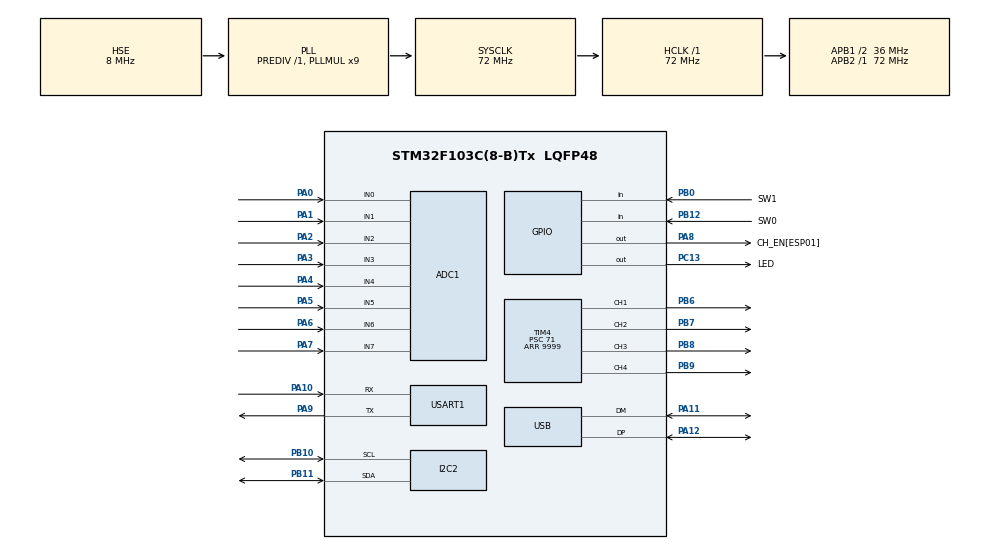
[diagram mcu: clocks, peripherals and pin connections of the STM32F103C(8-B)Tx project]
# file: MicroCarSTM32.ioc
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ADC1.Channel-0\#ChannelRegularConversion=ADC_CHANNEL_0
ADC1.Channel-1\#ChannelRegularConversion=ADC_CHANNEL_1
ADC1.Channel-2\#ChannelRegularConversion=ADC_CHANNEL_2
ADC1.Channel-3\#ChannelRegularConversion=ADC_CHANNEL_3
ADC1.Channel-4\#ChannelRegularConversion=ADC_CHANNEL_4
ADC1.Channel-5\#ChannelRegularConversion=ADC_CHANNEL_5
ADC1.Channel-6\#ChannelRegularConversion=ADC_CHANNEL_6
ADC1.Channel-7\#ChannelRegularConversion=ADC_CHANNEL_7
ADC1.NbrOfConversion=8
ADC1.NbrOfConversionFlag=1
ADC1.Rank-0\#ChannelRegularConversion=1
ADC1.Rank-1\#ChannelRegularConversion=2
ADC1.Rank-2\#ChannelRegularConversion=3
ADC1.Rank-3\#ChannelRegularConversion=4
ADC1.Rank-4\#ChannelRegularConversion=5
ADC1.Rank-5\#ChannelRegularConversion=6
ADC1.Rank-6\#ChannelRegularConversion=7
ADC1.Rank-7\#ChannelRegularConversion=8
ADC1.SamplingTime-0\#ChannelRegularConversion=ADC_SAMPLETIME_55CYCLES_5
ADC1.SamplingTime-1\#ChannelRegularConversion=ADC_SAMPLETIME_55CYCLES_5
ADC1.SamplingTime-2\#ChannelRegularConversion=ADC_SAMPLETIME_55CYCLES_5
ADC1.SamplingTime-3\#ChannelRegularConversion=ADC_SAMPLETIME_55CYCLES_5
ADC1.SamplingTime-4\#ChannelRegularConversion=ADC_SAMPLETIME_55CYCLES_5
ADC1.SamplingTime-5\#ChannelRegularConversion=ADC_SAMPLETIME_55CYCLES_5
ADC1.SamplingTime-6\#ChannelRegularConversion=ADC_SAMPLETIME_55CYCLES_5
ADC1.SamplingTime-7\#ChannelRegularConversion=ADC_SAMPLETIME_55CYCLES_5
ADC1.master=1
Dma.ADC1.0.Direction=DMA_PERIPH_TO_MEMORY
Dma.ADC1.0.Instance=DMA1_Channel1
Dma.ADC1.0.MemDataAlignment=DMA_MDATAALIGN_HALFWORD
Dma.ADC1.0.MemInc=DMA_MINC_ENABLE
Dma.ADC1.0.Mode=DMA_NORMAL
Dma.ADC1.0.PeriphDataAlignment=DMA_PDATAALIGN_HALFWORD
Dma.ADC1.0.PeriphInc=DMA_PINC_DISABLE
Dma.ADC1.0.Priority=DMA_PRIORITY_LOW
Dma.I2C2_RX.1.Direction=DMA_PERIPH_TO_MEMORY
Dma.I2C2_RX.1.Instance=DMA1_Channel5
Dma.I2C2_RX.1.MemDataAlignment=DMA_MDATAALIGN_BYTE
Dma.I2C2_RX.1.MemInc=DMA_MINC_ENABLE
Dma.I2C2_RX.1.Mode=DMA_NORMAL
Dma.I2C2_RX.1.PeriphDataAlignment=DMA_PDATAALIGN_WORD
Dma.I2C2_RX.1.PeriphInc=DMA_PINC_DISABLE
Dma.I2C2_RX.1.Priority=DMA_PRIORITY_LOW
Dma.I2C2_TX.2.Direction=DMA_MEMORY_TO_PERIPH
Dma.I2C2_TX.2.Instance=DMA1_Channel4
Dma.I2C2_TX.2.MemDataAlignment=DMA_MDATAALIGN_BYTE
Dma.I2C2_TX.2.MemInc=DMA_MINC_ENABLE
Dma.I2C2_TX.2.Mode=DMA_NORMAL
Dma.I2C2_TX.2.PeriphDataAlignment=DMA_PDATAALIGN_BYTE
Dma.I2C2_TX.2.PeriphInc=DMA_PINC_DISABLE
Dma.I2C2_TX.2.Priority=DMA_PRIORITY_LOW
Dma.Request0=ADC1
Dma.Request1=I2C2_RX
Dma.Request2=I2C2_TX
I2C2.I2C_Mode=I2C_Fast
Mcu.Family=STM32F1
Mcu.Name=STM32F103C(8-B)Tx
Mcu.Package=LQFP48
NVIC.DMA1_Channel1_IRQn=true\:0\:0\:false\:false\:true\:false\:true\:true
NVIC.DMA1_Channel4_IRQn=true\:0\:0\:false\:false\:true\:false\:true\:true
NVIC.DMA1_Channel5_IRQn=true\:0\:0\:false\:false\:true\:false\:true\:true
NVIC.I2C2_EV_IRQn=true\:0\:0\:false\:false\:true\:true\:true\:true
NVIC.PriorityGroup=NVIC_PRIORITYGROUP_4
NVIC.TIM1_UP_IRQn=true\:0\:0\:false\:false\:true\:true\:true\:true
NVIC.USART1_IRQn=true\:0\:0\:false\:false\:true\:true\:true\:true
NVIC.USB_LP_CAN1_RX0_IRQn=true\:0\:0\:false\:false\:true\:false\:true\:true
PA0-WKUP.Signal=ADCx_IN0
PA1.Signal=ADCx_IN1
PA10.Mode=Asynchronous
PA10.Signal=USART1_RX
PA11.Mode=Device
PA11.Signal=USB_DM
PA12.Mode=Device
PA12.Signal=USB_DP
PA13.Mode=Serial_Wire
PA13.Signal=SYS_JTMS-SWDIO
PA14.Mode=Serial_Wire
PA14.Signal=SYS_JTCK-SWCLK
PA2.Signal=ADCx_IN2
PA3.Signal=ADCx_IN3
PA4.Signal=ADCx_IN4
PA5.Signal=ADCx_IN5
PA6.Signal=ADCx_IN6
PA7.Signal=ADCx_IN7
PA8.GPIO_Label=CH_EN[ESP01]
PA8.Signal=GPIO_Output
PA9.Mode=Asynchronous
PA9.Signal=USART1_TX
PB0.GPIO_Label=SW1
PB0.GPIO_PuPd=GPIO_PULLUP
PB0.Signal=GPIO_Input
PB10.Mode=I2C
PB10.Signal=I2C2_SCL
PB11.Mode=I2C
PB11.Signal=I2C2_SDA
PB12.GPIO_Label=SW0
PB12.Signal=GPIO_Input
PB6.Signal=S_TIM4_CH1
PB7.Signal=S_TIM4_CH2
PB8.Signal=S_TIM4_CH3
PB9.Signal=S_TIM4_CH4
PC13-TAMPER-RTC.GPIO_Label=LED
PC13-TAMPER-RTC.Signal=GPIO_Output
PC14-OSC32_IN.Mode=LSE-External-Oscillator
PC14-OSC32_IN.Signal=RCC_OSC32_IN
PC15-OSC32_OUT.Mode=LSE-External-Oscillator
PC15-OSC32_OUT.Signal=RCC_OSC32_OUT
PD0-OSC_IN.Mode=HSE-External-Oscillator
PD0-OSC_IN.Signal=RCC_OSC_IN
PD1-OSC_OUT.Mode=HSE-External-Oscillator
PD1-OSC_OUT.Signal=RCC_OSC_OUT
ProjectManager.HeapSize=0x200
ProjectManager.StackSize=0x400
ProjectManager.TargetToolchain=STM32CubeIDE
RCC.ADCPresc=RCC_ADCPCLK2_DIV6
RCC.AHBFreq_Value=72000000
RCC.APB1CLKDivider=RCC_HCLK_DIV2
RCC.APB1Freq_Value=36000000
RCC.APB1TimFreq_Value=72000000
RCC.APB2Freq_Value=72000000
RCC.APB2TimFreq_Value=72000000
RCC.HCLKFreq_Value=72000000
RCC.PLLMUL=RCC_PLL_MUL9
RCC.SYSCLKFreq_VALUE=72000000
RCC.SYSCLKSource=RCC_SYSCLKSOURCE_PLLCLK
RCC.USBFreq_Value=48000000
RCC.USBPrescaler=RCC_USBCLKSOURCE_PLL_DIV1_5
SH.ADCx_IN0.0=ADC1_IN0,IN0
SH.ADCx_IN1.0=ADC1_IN1,IN1
SH.ADCx_IN2.0=ADC1_IN2,IN2
SH.ADCx_IN3.0=ADC1_IN3,IN3
SH.ADCx_IN4.0=ADC1_IN4,IN4
SH.ADCx_IN5.0=ADC1_IN5,IN5
SH.ADCx_IN6.0=ADC1_IN6,IN6
SH.ADCx_IN7.0=ADC1_IN7,IN7
SH.S_TIM4_CH1.0=TIM4_CH1,PWM Generation1 CH1
SH.S_TIM4_CH2.0=TIM4_CH2,PWM Generation2 CH2
SH.S_TIM4_CH3.0=TIM4_CH3,PWM Generation3 CH3
SH.S_TIM4_CH4.0=TIM4_CH4,PWM Generation4 CH4
TIM1.Period=249
TIM1.Prescaler=71
TIM4.Channel-PWM\ Generation1\ CH1=TIM_CHANNEL_1
TIM4.Channel-PWM\ Generation2\ CH2=TIM_CHANNEL_2
TIM4.Channel-PWM\ Generation3\ CH3=TIM_CHANNEL_3
TIM4.Channel-PWM\ Generation4\ CH4=TIM_CHANNEL_4
TIM4.Period=9999
TIM4.Prescaler=71
USART1.VirtualMode=VM_ASYNC
USB_DEVICE.APP_RX_DATA_SIZE=256
USB_DEVICE.APP_TX_DATA_SIZE=256
USB_DEVICE.CLASS_NAME_FS=CDC
USB_DEVICE.PID_CDC_FS=0x5740
USB_DEVICE.VID=0x483
USB_DEVICE.VirtualMode=Cdc
USB_DEVICE.VirtualModeFS=Cdc_FS
VP_TIM1_VS_ClockSourceINT.Mode=Internal
VP_TIM4_VS_ClockSourceINT.Mode=Internal
VP_USB_DEVICE_VS_USB_DEVICE_CDC_FS.Mode=CDC_FS
board=custom

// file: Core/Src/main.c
/* USER CODE BEGIN Header */
/**
  ******************************************************************************
  * @file           : main.c
  * @author			: Gerónimo Spiazzi
  * @brief          : Main program body
  ******************************************************************************
  * @attention
  *
  * Copyright (c) 2024 STMicroelectronics.
  * All rights reserved.
  *
  * This software is licensed under terms that can be found in the LICENSE file
  * in the root directory of this software component.
  * If no LICENSE file comes with this software, it is provided AS-IS.
  *
  ******************************************************************************
  */
/* USER CODE END Header */
#include "main.h"
#include "usb_device.h"

/* USER CODE BEGIN Includes */
#include <string.h>
#include "usbd_cdc_if.h"
#include "stm32f1xx_hal_flash.h"
#include "stm32f1xx_hal_flash_ex.h"
#include "ESP01.h"
#include "UNERBUS.h"
#include "BUTTON.h"
#include "INFRARED.h"
#include "MPU6050.h"
#include "OLED.h"
#include "PID.h"
#include "ENGINE.h"
/* USER CODE END Includes */

/* USER CODE BEGIN PTD */
typedef union {
	struct {
		uint8_t	b0:	1;
		uint8_t	b1:	1;
		uint8_t	b2:	1;
		uint8_t	b3:	1;
		uint8_t	b4:	1;
		uint8_t	b5:	1;
		uint8_t	b6:	1;
		uint8_t	b7:	1;
	} bit;
	uint8_t byte;
} _uFlag;

typedef union {
	uint8_t		u8[4];
	int8_t		i8[4];
	uint16_t	u16[2];
	int16_t		i16[2];
	uint32_t	u32;
	int32_t		i32;
} _uWork;

typedef enum {
	// Communication commands
	ACKNOWLEDGE = 0x0D,
	GET_LOCAL_IP = 0xF2,
    ALIVE = 0xF0,
    GET_FIRMWARE_INFO = 0xF1,
	UNKNOWNCMD = 0xFF,

	// 0xA_ : Sensors & Actuators (Read data)
    GET_IR_SENSORS = 0xA0,
	GET_MPU_DATA = 0xA2, //ACCELERATION
	GET_BUTTON_STATE = 0xA4, //BUTTONS
	GET_MOTOR_SPEED = 0xA6,

	// 0xB_ : Sensors (Configuration and calibration)
	SET_IR_CALIBRATION = 0xB0, //CALIBRATION

	// 0xC_ : Actuators and software configuration
	SET_MOTOR_TEST = 0xC0, //TEST_ENGINE
	SET_PWM_CONFIG = 0xC2,
	SET_BATTERY_VOLTAGE = 0xC4,

	// 0xD_ : PID Configuration
	// Turn PID
	SET_PID_TURN_GAINS = 0xD0, //SET_PID
	GET_PID_TURN_GAINS = 0xD1,

	// Wall PID
	SET_PID_WALL_GAINS = 0xD2,
	GET_PID_WALL_GAINS = 0xD3,

	// Stop PID
	SET_PID_STOP_GAINS = 0xD6,
	GET_PID_STOP_GAINS = 0xD7,

	// Movement parameters
	SET_TURN_SPEED = 0xD8,
	SET_WALL_SPEED = 0xDA,

	// Maze status
	SET_ROBOT_MODE = 0xE0,

	GET_CURRENT_ACTION		= 0xEA,

	SET_MAZE_TARGET			= 0xEC,
	SET_MAZE_START			= 0xED,

	GET_INTERSECTION_TYPE	= 0xEE,
	GET_MAP_INFO			= 0xEF,
	GET_SPECIAL_CELL		= 0xE5,

	// Stream Telemetry Mode
	STREAM_TELEMETRY		= 0xE3,
} Command_e;

typedef enum {
	DISPLAY_MENU,
	DISPLAY_IR_SENSORS,
	DISPLAY_MPU,
	DISPLAY_WIFI,
	DISPLAY_MOTORS,
	DISPLAY_SOFTWARE,
	DISPLAY_RUN,
	DISPLAY_RUN_MODE_SELECT,
	DISPLAY_CLEAR,
	DISPLAY_CONFIG_START,
	DISPLAY_CONFIG_TARGET,
	DISPLAY_END_SCREEN,
} DisplayPage_e;

typedef enum {
	MENU_START = 0,
	MENU_IR_DATA,
	MENU_MPU_DATA,
	MENU_WIFI,
	MENU_DRIVE_MOTOR,
	MENU_SOFTWARE_INFO,
	MENU_MAX_OPTIONS,
} MenuOptions_e;

typedef enum {
	MODE_IDLE,
	MODE_FINDING_MARKS,
	MODE_EXPLORING_MAZE,
//	MODE_MAZE_RUNNER,
} Robot_Mode_e;

typedef enum {
	ACTION_IDLE,
	ACTION_FOLLOW_WALL,
	ACTION_CENTER_IN_CELL,
	ACTION_AFTER_TURN,
	ACTION_TURN_PIVOT,
	ACTION_BACK_WALL_ALIGN,
	ACTION_MOTOR_TEST,
} Robot_Action_e;

typedef enum {
	NORTH = 0,
	EAST = 1,
	SOUTH = 2,
	WEST = 3,
} Map_Direction_e;

typedef enum {
	// [Left | Front | Right] -> (L << 2) | (F << 1) | R
	INTERSECTION_CROSSROAD			= 0x00,	// 0b000
	INTERSECTION_LEFT_FRONT_OPEN	= 0x01,	// 0b001
	INTERSECTION_T_ROAD				= 0x02, // 0b010
	INTERSECTION_LEFT_SQUARE		= 0x03,	// 0b011
	INTERSECTION_RIGHT_FRONT_OPEN	= 0x04, // 0b100
	INTERSECTION_UNKNOWN			= 0x05,	// 0b101 Hall
	INTERSECTION_RIGHT_SQUARE		= 0x06,	// 0b110
	INTERSECTION_DEAD_END			= 0x07,	// 0b111
} IntersectionType_e;

typedef enum {
	CELL_INSIDE_CELL,		// Robot navigating inside the cell, normal state
	CELL_FRONT_LINE,		// Front-under sensor detected the line
	CELL_REAR_LINE,			// Rear-under sensor detected the line
	CELL_CROSS_FINISHED,	// Rear-under sensor lost the line (robot is inside a new cell)
//	CELL_ON_MARK,			//
//	CELL_EXITING_MARK,		//
} CellCrossingState_e;

typedef struct {
	uint8_t t1ms;
	uint8_t t10ms;
	uint8_t t20ms;
	uint8_t t100ms;
	uint8_t t500ms;
	uint8_t t1s;
	uint8_t tOutAliveUDP;
} Time_s;

typedef struct {
	uint8_t walls;
	uint8_t visited;
	uint8_t cost;
} CellData_s;

typedef struct {
	CellData_s maze[8][8];
	uint8_t currentX;
	uint8_t currentY;
	uint8_t targetX;
	uint8_t targetY;
} Map_Position_s;

typedef struct {
    uint8_t x;
    uint8_t y;
} Point_s;

typedef struct {
	uint32_t time_frontLineDetect;
	uint32_t time_frontLineLost;
	uint32_t time_rearLineDetect;
	uint32_t time_rearLineLost;
	uint32_t currentVelocity_mm_s;
	uint32_t time_dt_ms;
} VELOCITY_Handle_s;

/*
 * HAL_FLASH_Unlock();
 * CONFIGURAR ESTRUCTURA ERASE
 * EJECUTAR HAL_FLASHEx_Erase
 * Pasar toda la información a la Flash con HAL_FLASH_Program
 * HAL_FLASH_Lock();
 */

/* USER CODE END PTD */

/* USER CODE BEGIN PD */
// Communication buffers size macros
#define SIZEBUFRXPC				128
#define SIZEBUFTXPC				256
#define SIZEBUFRXESP01			128
#define SIZEBUFTXESP01			128

// Heart beat macros
#define	HEARTBEAT_IDLE			0xF4000000
#define	HEARTBEAT_WIFI_READY	0xF5000000
#define	HEARTBEAT_UDP_READY		0xF5400000

// Wi-Fi configuration macros
#define WIFI_SSID				"FCAL"//"FCAL" "InternetPlus_86aa10" "LabPrototip" "InternetPlus_8e2fbb"
#define WIFI_PASSWORD			"fcalconcordia.06-2019"//"fcalconcordia.06-2019" "wlan7955ef" "labproto" "Akhantos2340"
#define WIFI_UDP_REMOTE_IP		"111.22.333.44"//"172.23.229.43"//"192.168.1.18"	//La IP de la PC 172.23.229.43 "192.168.1.31"
#define WIFI_UDP_REMOTE_PORT	30010				//El puerto UDP en la PC
#define WIFI_UDP_LOCAL_PORT		30000

// Display design macros
#define MENU_ITEM_HEIGHT		12 // 10px fuente + 2px espacio
#define MENU_START_Y			14 // Debajo de la línea del header
#define MAX_VISIBLE_ITEMS		4 // Cuántas opciones caben en pantalla a la vez

// Flags macros
#define on1MS					flag1.bit.b0
#define MPU_READ_REQUEST		flag1.bit.b1
#define OLED_UPDATE_REQUEST		flag1.bit.b2
#define I2C_BUS_IS_BUSY			flag1.bit.b3
#define LINE_DETECTED_TURNING	flag1.bit.b4
#define SHOW_EYES_SCREEN		flag1.bit.b5

// Timer counter macros
#define t1MS					timeCounter.t1ms
#define t10MS					timeCounter.t10ms
#define t20MS					timeCounter.t20ms
#define t100MS					timeCounter.t100ms
#define t500MS					timeCounter.t500ms
#define t1S						timeCounter.t1s
#define tOutAliveUDP 			timeCounter.tOutAliveUDP

// Voltage of the batteries (used for PID control of the engines)
#define PID_VOLTAGE					800
#define CURRENT_VOLTAGE				811

// Turn control macros
#define SMOOTH_TURN_OUTER_SPEED		-65
#define SMOOTH_TURN_INNER_SPEED		-35
#define TURN_THRESHOLD				7*YAW_SCALE

#define SMOOTH_TURN_BASE_SPEED		-50
#define SMOOTH_EXIT_OFFSET 			(7 * YAW_SCALE)
#define TURN_MIN_PWM				30

// Wall follow control macros
// Millimeter IR Thresholds
#define WALL_FRONT_THRESHOLD_MM		10
#define WALL_TARGET_DISTANCE_MM		50

// RAW IR THRESHOLDS
#define WALL_FRONT_THRESHOLD		2700 	// Para no chocar la pared de enfrente 			// Casa: 1050 	// Facu: 1200
#define OPEN_CORNER_THRESHOLD		190 	// Para detectar la apertura de una esquina 	// Casa: 320 	// Facu: 170
#define ONE_WALL_TARGET_DISTANCE 	1100 	// Para seguir la pared 						// Casa: 1400 	// Facu: 1100
#define OBJECT_DETECTION_THRESHOLD	180 	// Para detectar pared al otro lado del cruce 	// Casa: 150 	// Facu: 190
#define LINE_DETECTION_THRESHOLD	1600 	// Para detectar la línea de la celda 			// Casa: 1400 	// Facu: 1500
#define LATERAL_WALL_THRESHOLD		800 	// Detectar si hay pared al lado				// Casa: 500 	// Facu: 450

#define WALL_ERROR_DEADZONE			2
#define GYRO_COMPENSATION_GAIN		4 		// Ponderación del giroscopio para mantenerse recto en un cruce con una sola pared

#define DIST_RIGHT_IR				myInfraredValues.millimeterSamples[0]
#define DIST_DIAG_RIGHT_IR			myInfraredValues.millimeterSamples[1]
#define DIST_FRONT_RIGHT_IR			myInfraredValues.millimeterSamples[2]
#define DIST_FRONT_UNDER_IR			myInfraredValues.millimeterSamples[3]
#define DIST_FRONT_LEFT_IR			myInfraredValues.millimeterSamples[4]
#define DIST_DIAG_LEFT_IR			myInfraredValues.millimeterSamples[5]
#define DIST_LEFT_IR				myInfraredValues.millimeterSamples[6]
#define DIST_REAR_UNDER_IR			myInfraredValues.millimeterSamples[7]

#define FILTERED_RIGHT_IR			myInfraredValues.filteredSamples[0]
#define FILTERED_DIAG_RIGHT_IR		myInfraredValues.filteredSamples[1]
#define FILTERED_FRONT_RIGHT_IR		myInfraredValues.filteredSamples[2]
#define FILTERED_FRONT_UNDER_IR		myInfraredValues.filteredSamples[3]
#define FILTERED_FRONT_LEFT_IR		myInfraredValues.filteredSamples[4]
#define FILTERED_DIAG_LEFT_IR		myInfraredValues.filteredSamples[5]
#define FILTERED_LEFT_IR			myInfraredValues.filteredSamples[6]
#define FILTERED_REAR_UNDER_IR		myInfraredValues.filteredSamples[7]

#define DISTANCE_FRONT_TO_REAR_IR	 85 // Millimeter
#define IR_CENTER_DISTANCE_THRESHOLD 1400

#define PERCEPTION_RIGHT			flagsIR.bit.b0
#define PERCEPTION_DIAG_RIGHT		flagsIR.bit.b1
#define	PERCEPTION_FRONT_RIGHT		flagsIR.bit.b2
#define PERCEPTION_FRONT_LEFT		flagsIR.bit.b4
#define PERCEPTION_DIAG_LEFT		flagsIR.bit.b5
#define PERCEPTION_LEFT				flagsIR.bit.b6

#define WALL_NORTH 0x01
#define WALL_EAST 0x02
#define WALL_SOUTH 0x04
#define WALL_WEST 0x08
/* USER CODE END PD */

ADC_HandleTypeDef hadc1;
DMA_HandleTypeDef hdma_adc1;

I2C_HandleTypeDef hi2c2;
DMA_HandleTypeDef hdma_i2c2_rx;
DMA_HandleTypeDef hdma_i2c2_tx;

TIM_HandleTypeDef htim1;
TIM_HandleTypeDef htim4;

UART_HandleTypeDef huart1;

/* USER CODE BEGIN PV */
////////////////////////////// TYPEDEF HANDLERS ///////////////////////////////
volatile _uFlag flag1;
_uWork w;
DisplayPage_e currentPage;
MenuOptions_e currentMenu;
Command_e cmds;
Time_s timeCounter;

static _uFlag flagsIR;
static InfraredHandle_s myInfraredValues;
static MPU_Handle_s myMpuValues;
static OLED_Handle_s myOled;
static PIDHandle_s myTurnValues, myWallValues, mySmoothTurnValues, myStopValues, myReverseValues;
static ENGINE_Handle_s myEngines;
static BUTTON_Handle_s myButton1;
static VELOCITY_Handle_s myVelocity;
/////////////////////////// COMMUNICATION VARIABLES ////////////////////////////
_sESP01Handle esp01;
_sUNERBUSHandle unerbusPC;
_sUNERBUSHandle unerbusESP01;

char localIP[16];

uint8_t bufRXPC[SIZEBUFRXPC], bufTXPC[SIZEBUFTXPC];
uint8_t bufRXESP01[SIZEBUFRXESP01], bufTXESP01[SIZEBUFTXESP01], dataRXESP01;

uint8_t rxUSBData, newData;

static uint8_t i2c_start_timeout = 0;
////////////////////////////// HEARTBEAT VARIABLES /////////////////////////////
uint16_t mask, moveMask;

//////////////////////////// DISPLAY & MENU VARIABLES //////////////////////////
const char* menuItems[] = {
	"Run", 		// "Run           ",
    "Infrared", // "Infrared      ",
    "Motion",
    "Wi-Fi",
    "Motors", 	// "Motors        ",
    "Software"
};

const int8_t totalMenuItems = 6;
int8_t currentSelection;
int8_t scrollOffset;
uint8_t runConfigStep = 0;
//////////////////////////////// OTHER VARIABLES ///////////////////////////////
// Robot control and algorithm variables
Robot_Mode_e currentMode;
Robot_Mode_e selectedRunMode;
Robot_Action_e currentAction;

CellCrossingState_e cellState;

Map_Position_s currentPosition;
Map_Direction_e currentDirection = NORTH;

IntersectionType_e detectedIntersection;

uint8_t intersectionType;
int16_t pivotDegreesTarget;

uint8_t markDetected = 0, marksCount = 0, currentMarkTargetIndex = 0;;
Point_s markLocations[3];

uint8_t showIrInMillimeters;

uint8_t activeLeftWall = 0;
uint8_t activeRightWall = 0;

int32_t wallFollowTargetYaw = 0;
uint16_t referenceLeftWall = 0, referenceRightWall = 0;

uint8_t exitTurn;
uint32_t timeToCenter, centeringStartTime, alignStartTime;

uint8_t marksFound;

char strAux[20];

// EEPROM SIMULATION
const uint8_t varEeprom[] __attribute__ ((__section__ (".configeeprom"))) =
		{0xff, 0xff, 0xff, 0xff, 0xff, 0xff, 0xff, 0xff, 0xff, 0xff, 0xff, 0xff, 0xff, 0xff, 0xff, 0xff,
		0xff, 0xff, 0xff, 0xff, 0xff, 0xff, 0xff, 0xff, 0xff, 0xff, 0xff, 0xff, 0xff, 0xff, 0xff, 0xff,
		0xff, 0xff, 0xff, 0xff, 0xff, 0xff, 0xff, 0xff, 0xff, 0xff, 0xff, 0xff, 0xff, 0xff, 0xff, 0xff,
		0xff, 0xff, 0xff, 0xff, 0xff, 0xff, 0xff, 0xff, 0xff, 0xff, 0xff, 0xff, 0xff, 0xff, 0xff, 0xff,
		0xff, 0xff, 0xff, 0xff, 0xff, 0xff, 0xff, 0xff, 0xff, 0xff, 0xff, 0xff, 0xff, 0xff, 0xff, 0xff,
		0xff, 0xff, 0xff, 0xff, 0xff, 0xff, 0xff, 0xff, 0xff, 0xff, 0xff, 0xff, 0xff, 0xff, 0xff, 0xff,
		0xff, 0xff, 0xff, 0xff, 0xff, 0xff, 0xff, 0xff, 0xff, 0xff, 0xff, 0xff, 0xff, 0xff, 0xff, 0xff,
		0xff, 0xff, 0xff, 0xff, 0xff, 0xff, 0xff, 0xff, 0xff, 0xff, 0xff, 0xff, 0xff, 0xff, 0xff, 0xff,
		0xff, 0xff, 0xff, 0xff, 0xff, 0xff, 0xff, 0xff, 0xff, 0xff, 0xff, 0xff, 0xff, 0xff, 0xff, 0xff,
		0xff, 0xff, 0xff, 0xff, 0xff, 0xff, 0xff, 0xff, 0xff, 0xff, 0xff, 0xff, 0xff, 0xff, 0xff, 0xff,
		0xff, 0xff, 0xff, 0xff, 0xff, 0xff, 0xff, 0xff, 0xff, 0xff, 0xff, 0xff, 0xff, 0xff, 0xff, 0xff,
		0xff, 0xff, 0xff, 0xff, 0xff, 0xff, 0xff, 0xff, 0xff, 0xff, 0xff, 0xff, 0xff, 0xff, 0xff, 0xff,
		0xff, 0xff, 0xff, 0xff, 0xff, 0xff, 0xff, 0xff, 0xff, 0xff, 0xff, 0xff, 0xff, 0xff, 0xff, 0xff,
		0xff, 0xff, 0xff, 0xff, 0xff, 0xff, 0xff, 0xff, 0xff, 0xff, 0xff, 0xff, 0xff, 0xff, 0xff, 0xff,
		0xff, 0xff, 0xff, 0xff, 0xff, 0xff, 0xff, 0xff, 0xff, 0xff, 0xff, 0xff, 0xff, 0xff, 0xff, 0xff,
		0xff, 0xff, 0xff, 0xfe, 0x00, 0x00, 0x00, 0x07, 0xff, 0xf0, 0x00, 0x00, 0x00, 0x00, 0xff, 0xff,
		0xff, 0xff, 0xff, 0xf0, 0x00, 0x00, 0x00, 0x07, 0xff, 0x80, 0x00, 0x00, 0x00, 0x00, 0xff, 0xff,
		0xff, 0xff, 0xff, 0x80, 0x00, 0x00, 0x00, 0x0f, 0xfe, 0x00, 0x00, 0x00, 0x00, 0x01, 0xff, 0xff,
		0xff, 0xff, 0xfe, 0x00, 0x00, 0x00, 0x00, 0x1f, 0xf8, 0x00, 0x00, 0x00, 0x00, 0x03, 0xff, 0xff,
		0xff, 0xff, 0xfc, 0x00, 0x00, 0x00, 0x00, 0x3f, 0xf0, 0x00, 0x00, 0x00, 0x00, 0x07, 0xff, 0xff,
		0xff, 0xff, 0xf8, 0x00, 0x00, 0x00, 0x00, 0x3f, 0xf0, 0x00, 0x00, 0x00, 0x00, 0x07, 0xff, 0xff,
		0xff, 0xff, 0xf0, 0x00, 0x00, 0x00, 0x00, 0x7f, 0xe0, 0x00, 0x00, 0x00, 0x00, 0x0f, 0xff, 0xff,
		0xff, 0xff, 0xe0, 0x00, 0x00, 0x00, 0x00, 0xff, 0xe0, 0x00, 0x00, 0x00, 0x00, 0x1f, 0xff, 0xff,
		0xff, 0xff, 0xc0, 0x00, 0x00, 0x00, 0x01, 0xff, 0xc0, 0x00, 0x00, 0x00, 0x00, 0x3f, 0xff, 0xff,
		0xff, 0xff, 0x80, 0x00, 0x7f, 0xff, 0xff, 0xff, 0xc0, 0x03, 0xff, 0xff, 0xff, 0xff, 0xff, 0xff,
		0xff, 0xff, 0x80, 0x03, 0xff, 0xff, 0xff, 0xff, 0xc0, 0x07, 0xff, 0xff, 0xff, 0xff, 0xff, 0xff,
		0xff, 0xff, 0x00, 0x07, 0xff, 0xff, 0xff, 0xff, 0xc0, 0x0f, 0xff, 0xff, 0xff, 0xff, 0xff, 0xff,
		0xff, 0xff, 0x00, 0x0f, 0xff, 0xff, 0xff, 0xff, 0xc0, 0x07, 0xff, 0xff, 0xff, 0xff, 0xff, 0xff,
		0xff, 0xff, 0x00, 0x1f, 0xfc, 0x00, 0x00, 0x07, 0xc0, 0x07, 0xff, 0xff, 0xff, 0xff, 0xff, 0xff,
		0xff, 0xff, 0x00, 0x1f, 0xf8, 0x00, 0x00, 0x07, 0xe0, 0x00, 0x00, 0x00, 0x00, 0x7f, 0xff, 0xff,
		0xff, 0xfe, 0x00, 0x3f, 0xf0, 0x00, 0x00, 0x07, 0xe0, 0x00, 0x00, 0x00, 0x00, 0x0f, 0xff, 0xff,
		0xff, 0xfe, 0x00, 0x3f, 0xe0, 0x00, 0x00, 0x07, 0xf0, 0x00, 0x00, 0x00, 0x00, 0x01, 0xff, 0xff,
		0xff, 0xfe, 0x00, 0x3f, 0xc0, 0x00, 0x00, 0x07, 0xf8, 0x00, 0x00, 0x00, 0x00, 0x00, 0xff, 0xff,
		0xff, 0xfe, 0x00, 0x3f, 0x80, 0x00, 0x00, 0x07, 0xfc, 0x00, 0x00, 0x00, 0x00, 0x00, 0xff, 0xff,
		0xff, 0xff, 0x00, 0x3f, 0x00, 0x00, 0x00, 0x07, 0xff, 0x00, 0x00, 0x00, 0x00, 0x00, 0x7f, 0xff,
		0xff, 0xff, 0x00, 0x3f, 0x00, 0x00, 0x00, 0x07, 0xff, 0xe0, 0x00, 0x00, 0x00, 0x00, 0x7f, 0xff,
		0xff, 0xff, 0x00, 0x1f, 0xff, 0xff, 0xc0, 0x07, 0xff, 0xff, 0xff, 0xff, 0xfe, 0x00, 0x3f, 0xff,
		0xff, 0xff, 0x00, 0x0f, 0xff, 0xff, 0xc0, 0x07, 0xff, 0xff, 0xff, 0xff, 0xfe, 0x00, 0x3f, 0xff,
		0xff, 0xff, 0x80, 0x07, 0xff, 0xff, 0xc0, 0x07, 0xff, 0xff, 0xff, 0xff, 0xff, 0x00, 0x3f, 0xff,
		0xff, 0xff, 0x80, 0x03, 0xff, 0xff, 0xc0, 0x07, 0xff, 0xff, 0xff, 0xff, 0xfe, 0x00, 0x3f, 0xff,
		0xff, 0xff, 0xc0, 0x00, 0xff, 0xff, 0xc0, 0x07, 0xff, 0xff, 0xff, 0xff, 0xfe, 0x00, 0x3f, 0xff,
		0xff, 0xff, 0xc0, 0x00, 0x00, 0x00, 0x00, 0x07, 0xff, 0x00, 0x00, 0x00, 0x00, 0x00, 0x7f, 0xff,
		0xff, 0xff, 0xe0, 0x00, 0x00, 0x00, 0x00, 0x07, 0xfe, 0x00, 0x00, 0x00, 0x00, 0x00, 0x7f, 0xff,
		0xff, 0xff, 0xf0, 0x00, 0x00, 0x00, 0x00, 0x07, 0xfc, 0x00, 0x00, 0x00, 0x00, 0x00, 0x7f, 0xff,
		0xff, 0xff, 0xf8, 0x00, 0x00, 0x00, 0x00, 0x07, 0xf8, 0x00, 0x00, 0x00, 0x00, 0x00, 0xff, 0xff,
		0xff, 0xff, 0xfc, 0x00, 0x00, 0x00, 0x00, 0x07, 0xf0, 0x00, 0x00, 0x00, 0x00, 0x00, 0xff, 0xff,
		0xff, 0xff, 0xff, 0x00, 0x00, 0x00, 0x00, 0x07, 0xf0, 0x00, 0x00, 0x00, 0x00, 0x01, 0xff, 0xff,
		0xff, 0xff, 0xff, 0xc0, 0x00, 0x00, 0x00, 0x07, 0xe0, 0x00, 0x00, 0x00, 0x00, 0x07, 0xff, 0xff,
		0xff, 0xff, 0xff, 0xf8, 0x00, 0x00, 0x00, 0x07, 0xc0, 0x00, 0x00, 0x00, 0x00, 0x1f, 0xff, 0xff,
		0xff, 0xff, 0xff, 0xff, 0x80, 0x00, 0x00, 0x07, 0x80, 0x00, 0x00, 0x00, 0x01, 0xff, 0xff, 0xff,
		0xff, 0xff, 0xff, 0xff, 0xff, 0xff, 0xff, 0xff, 0xff, 0xff, 0xff, 0xff, 0xff, 0xff, 0xff, 0xff,
		0xff, 0xff, 0xff, 0xff, 0xff, 0xff, 0xff, 0xff, 0xff, 0xff, 0xff, 0xff, 0xff, 0xff, 0xff, 0xff,
		0xff, 0xff, 0xff, 0xff, 0xff, 0xff, 0xff, 0xff, 0xff, 0xff, 0xff, 0xff, 0xff, 0xff, 0xff, 0xff,
		0xff, 0xff, 0xff, 0xff, 0xff, 0xff, 0xff, 0xff, 0xff, 0xff, 0xff, 0xff, 0xff, 0xff, 0xff, 0xff,
		0xff, 0xff, 0xff, 0xff, 0xff, 0xff, 0xff, 0xff, 0xff, 0xff, 0xff, 0xff, 0xff, 0xff, 0xff, 0xff,
		0xff, 0xff, 0xff, 0xff, 0xff, 0xff, 0xff, 0xff, 0xff, 0xff, 0xff, 0xff, 0xff, 0xff, 0xff, 0xff,
		0xff, 0xff, 0xff, 0xff, 0xff, 0xff, 0xff, 0xff, 0xff, 0xff, 0xff, 0xff, 0xff, 0xff, 0xff, 0xff,
		0xff, 0xff, 0xff, 0xff, 0xff, 0xff, 0xff, 0xff, 0xff, 0xff, 0xff, 0xff, 0xff, 0xff, 0xff, 0xff,
		0xff, 0xff, 0xff, 0xff, 0xff, 0xff, 0xff, 0xff, 0xff, 0xff, 0xff, 0xff, 0xff, 0xff, 0xff, 0xff,
		0xff, 0xff, 0xff, 0xff, 0xff, 0xff, 0xff, 0xff, 0xff, 0xff, 0xff, 0xff, 0xff, 0xff, 0xff, 0xff,
		0xff, 0xff, 0xff, 0xff, 0xff, 0xff, 0xff, 0xff, 0xff, 0xff, 0xff, 0xff, 0xff, 0xff, 0xff, 0xff,
		0xff, 0xff, 0xff, 0xff, 0xff, 0xff, 0xff, 0xff, 0xff, 0xff, 0xff, 0xff, 0xff, 0xff, 0xff, 0xff,
		0xff, 0xff, 0xff, 0xff, 0xff, 0xff, 0xff, 0xff, 0xff, 0xff, 0xff, 0xff, 0xff, 0xff, 0xff, 0xff,
		0xff, 0xff, 0xff, 0xff, 0xff, 0xff, 0xff, 0xff, 0xff, 0xff, 0xff, 0xff, 0xff, 0xff, 0xff, 0xff};
//__attribute__ ((__section__ (".configeeprom"), used)) uint32_t varEeprom;

/* USER CODE END PV */

void SystemClock_Config(void);
static void MX_GPIO_Init(void);
static void MX_DMA_Init(void);
static void MX_ADC1_Init(void);
static void MX_I2C2_Init(void);
static void MX_TIM1_Init(void);
static void MX_TIM4_Init(void);
static void MX_USART1_UART_Init(void);
/* USER CODE BEGIN PFP */
////////////////////// COMMUNICATION FUNCTIONS PROTOTYPES //////////////////////

void USBReceive(uint8_t *buf, uint16_t len);
void ESP01DoCHPD(uint8_t value);
int ESP01WriteUSARTByte(uint8_t value);
void ESP01WriteByteToBufRX(uint8_t value);
void ESP01ChangeState(_eESP01STATUS esp01State);

void DecodeCMD(struct UNERBUSHandle *aBus, uint8_t iStartData);

const char* GetFirmwareVersion_String(void);

void I2C_State_Control(void);
//void I2C_Bus_Recovery(void);
void MPU_Read_Completed_Callback(void *context);
void OLED_Write_Completed_Callback(void *context);
///////////////////////// TIMING FUNCTIONS PROTOTYPES //////////////////////////

void Do1ms();
void Do10ms();
void Do20ms();
void Do100ms();
void Do1s();

///////////////////////// PROGRAM FUNCTIONS PROTOTYPES /////////////////////////
void Robot_StateMachine(void);
void Robot_Stop(void);
void Robot_ExploreMaze(void);
void Robot_FollowWall_Control(void);
void Robot_Turn_Control(int16_t degreesToTurn);
void Robot_CheckCellCrossing(void);
int8_t Robot_CalculateNextMove(void);

IntersectionType_e Robot_IdentifyIntersection(void);

void Robot_ProcessIntersection(uint8_t hasLeftWall, uint8_t hasFrontWall, uint8_t hasRightWall);
void Mark_SaveLocation(uint8_t x, uint8_t y);
uint8_t Map_SetTargetToNearestUnvisited(void);

void Robot_StartFindingMarks(void);

void FloodFill_Calculate(void);

void Map_AddWallToMap(uint8_t x, uint8_t y, uint8_t dir);
void Map_UpdateCell(uint8_t leftWall, uint8_t frontWall, uint8_t rightWall);
void Map_UpdateDirection(int8_t turnDir);
void Map_UpdateCoordinates(void);

void DrawRobotEyes(OLED_Handle_s *handle, IntersectionType_e intersection, Robot_Action_e action, int16_t turnTarget);
void ChangeDisplayPage(DisplayPage_e page);

void Heartbeat();

void SetMotorSpeed(uint8_t leftPower, uint8_t rightPower);

/* USER CODE END PFP */

/* USER CODE BEGIN 0 */
////////////////////////////// CALLBACKS FUNCTIONS //////////////////////////////
void HAL_TIM_PeriodElapsedCallback(TIM_HandleTypeDef *htim){
	if(htim->Instance == TIM1){
		t1MS--;
		if(!t1MS){
			on1MS = 1;
			t1MS = 4;
		}

		HAL_ADC_Start_DMA(&hadc1, (uint32_t *)&myInfraredValues.rawSamples, ADC_CHANNELS);
	}
}

void HAL_ADC_ConvCpltCallback(ADC_HandleTypeDef* hadc){
	Infrared_Filter(&myInfraredValues);
}

void HAL_UART_RxCpltCallback(UART_HandleTypeDef *huart){
	if(huart->Instance == USART1){
		ESP01_WriteRX(dataRXESP01);
		HAL_UART_Receive_IT(&huart1, &dataRXESP01, 1);
	}
}

//////////////////////////// COMMUNICATION FUNCTIONS ////////////////////////////
void ESP01DoCHPD(uint8_t value){
	HAL_GPIO_WritePin(CH_EN_GPIO_Port, CH_EN_Pin, value);
}

int ESP01WriteUSARTByte(uint8_t value){
	if(__HAL_UART_GET_FLAG(&huart1, USART_SR_TXE)){
		USART1->DR = value;
		return 1;
	}
	return 0;
}

void ESP01WriteByteToBufRX(uint8_t value){
	UNERBUS_ReceiveByte(&unerbusESP01, value);
}

void ESP01ChangeState(_eESP01STATUS esp01State){
/*
	switch((uint32_t)esp01State){
	case ESP01_WIFI_CONNECTED:
		heartbeat = HEARTBEAT_WIFI_READY;
		break;
	case ESP01_UDPTCP_CONNECTED:
		heartbeat = HEARTBEAT_UDP_READY;
		break;
	case ESP01_UDPTCP_DISCONNECTED:
		heartbeat = HEARTBEAT_WIFI_READY;
		break;
	case ESP01_WIFI_DISCONNECTED:
		heartbeat = HEARTBEAT_IDLE;
		break;
	}
*/
}

const char* GetFirmwareVersion_String(void){
    static char firmwareVersionStr[32];

    // Macro __DATE__ returns "mm dd yyyy" (example: "May 31 2024")
    // Macro __TIME__ returns "hh:mm:ss" (example. "15:45:00")
    sprintf(firmwareVersionStr, "%s - %s", __DATE__, __TIME__);

    return firmwareVersionStr;
}

void MPU_Read_Completed_Callback(void *context) {
	// MPU Reading completed
    // 'context' is &myMpuValues.
    MPU_Handle_s *mpuHandle = (MPU_Handle_s *)context;

    // 1. Process the new data
    MPU6050_ProcessRawData(mpuHandle);

    // 2. Freed I2C bus
    I2C_BUS_IS_BUSY = 0;
}

//================================================================================
// CALLBACK when I2C Writing via DMA ends (Tx)
//================================================================================
void OLED_Write_Completed_Callback(void *context) {
    myOled.updatePageState++;
    if (myOled.updatePageState > 3) {
        myOled.updatePageState = 0;   // Reset for the next page
        myOled.currentPageToUpdate++; // Go to next page
    }

    I2C_BUS_IS_BUSY = 0;
}

void I2C_State_Control(void){
	if (I2C_BUS_IS_BUSY) {

//		if ((HAL_GetTick() - i2c_start_timeout) > 15) {
//			I2C_Bus_Recovery();
//		}
		return;
	}

	if (MPU_READ_REQUEST) {
		MPU_READ_REQUEST = 0;
		I2C_BUS_IS_BUSY = 1;
		i2c_start_timeout = HAL_GetTick();
		MPU6050_Read_Data(&myMpuValues);
		return;
	} else if (myOled.currentPageToUpdate < 8) {
		I2C_BUS_IS_BUSY = 1;
		i2c_start_timeout = HAL_GetTick();
		OLED_UpdateSingleStep_DMA(&myOled);
	}
}

//void I2C_Bus_Recovery(void) {
//	// Detener cualquier transferencia DMA que haya quedado a medias
//	if (hi2c2.hdmatx != NULL) HAL_DMA_Abort(hi2c2.hdmatx);
//	if (hi2c2.hdmarx != NULL) HAL_DMA_Abort(hi2c2.hdmarx);
//
//	// Reseteo violento por hardware del periférico I2C2
//	__HAL_RCC_I2C2_FORCE_RESET();
//	__NOP();
//	__NOP();
//	__NOP();
//	__NOP();
//	__HAL_RCC_I2C2_RELEASE_RESET();
//
//	// Reinicializar el periférico con la configuración original
//	MX_I2C2_Init();
//
//	// Liberar el bus
//	I2C_BUS_IS_BUSY = 0;
//	MPU_READ_REQUEST = 0;
//
//	// Resetear la máquina de estados del OLED.
//	// Lo mandamos a 8 para que aborte el cuadro actual y espere a que
//	// Do100ms() pida un cuadro nuevo. Esto evita glitches gráficos.
//	myOled.updatePageState = 0;
//	myOled.currentPageToUpdate = 8;
//}

void DecodeCMD(struct UNERBUSHandle *aBus, uint8_t iStartData){
	uint8_t id;
	uint8_t length = 0;

	uint8_t buf[24];
	id = UNERBUS_GetUInt8(aBus);
	switch(id){
	case GET_LOCAL_IP:
		UNERBUS_Write(aBus, (uint8_t *)ESP01_GetLocalIP(), 16);
		length = 17;
		break;
	case ALIVE: //ALIVE
		UNERBUS_WriteByte(aBus, ACKNOWLEDGE);
		length = 2;
		break;
	case GET_FIRMWARE_INFO:
		const char* versionStr = GetFirmwareVersion_String();
		UNERBUS_Write(aBus, (uint8_t*)versionStr, strlen(versionStr));
		length = strlen(versionStr) + 1;
		break;
	case GET_IR_SENSORS:
		for(uint8_t i = 0; i < ADC_CHANNELS; i++) {
			UNERBUS_WriteByte(aBus, myInfraredValues.filteredSamples[i] & 0xFF);
			UNERBUS_WriteByte(aBus, (myInfraredValues.filteredSamples[i] >> 8) & 0xFF);
		}
		length = (ADC_CHANNELS * 2) + 1;
		//UNERBUS_Write(aBus, myInfraredValues.millimeterSamples, ADC_CHANNELS);
		//length = ADC_CHANNELS + 1;
		break;
	case SET_IR_CALIBRATION:
//		for(uint8_t i = 0; i < 20; i++)
//			myInfraredValues.lookUp[i] = UNERBUS_GetInt16(aBus);
		break;
	case GET_MPU_DATA:
		MPU6050_Compose_Number(&myMpuValues, buf);
		UNERBUS_Write(aBus, buf, MPU_DATA_BUFFER_SIZE);
		length = MPU_DATA_BUFFER_SIZE + 1;
		break;
	case SET_MOTOR_TEST:
		int8_t leftSpeed = UNERBUS_GetInt8(aBus);
		int8_t rightSpeed = UNERBUS_GetInt8(aBus);

		currentAction = ACTION_MOTOR_TEST;

		ENGINE_SetLeftSpeed(&myEngines, leftSpeed);
		ENGINE_SetRightSpeed(&myEngines, rightSpeed);

		if (leftSpeed == 0 && rightSpeed == 0)
			currentAction = ACTION_IDLE;
		break;
	case SET_PWM_CONFIG:
		myEngines.pwmMaxPeriod = UNERBUS_GetUInt8(aBus);
		__HAL_TIM_SET_PRESCALER(&htim4, myEngines.pwmMaxPeriod);
		__HAL_TIM_SET_AUTORELOAD(&htim4, UNERBUS_GetUInt8(aBus));
		break;
	case SET_BATTERY_VOLTAGE:
		ENGINE_SetBatteryVoltage(&myEngines, UNERBUS_GetUInt16(aBus));
		break;
	case SET_PID_TURN_GAINS:
		myTurnValues.Kp = UNERBUS_GetUInt16(aBus);
		myTurnValues.Ki = UNERBUS_GetUInt16(aBus);
		myTurnValues.Kd = UNERBUS_GetUInt16(aBus);
		myTurnValues.outputMin = UNERBUS_GetInt8(aBus);
		myTurnValues.outputMax = UNERBUS_GetInt8(aBus);
		myTurnValues.base = UNERBUS_GetInt8(aBus);
		break;
	case GET_PID_TURN_GAINS:
		buf[0] = myTurnValues.Kp & 0xFF;
		buf[1] = (myTurnValues.Kp >> 8) & 0xFF;

		buf[2] = myTurnValues.Ki & 0xFF;
		buf[3] = (myTurnValues.Ki >> 8) & 0xFF;

		buf[4] = myTurnValues.Kd & 0xFF;
		buf[5] = (myTurnValues.Kd >> 8) & 0xFF;

		buf[6] = myTurnValues.outputMin;
		buf[7] = myTurnValues.outputMax;
		buf[8] = myTurnValues.base;

		UNERBUS_Write(aBus, buf, 9);
		length = 10;
		break;
	case SET_PID_WALL_GAINS:
		myWallValues.Kp = UNERBUS_GetUInt16(aBus);
		myWallValues.Ki = UNERBUS_GetUInt16(aBus);
		myWallValues.Kd = UNERBUS_GetUInt16(aBus);
		myWallValues.outputMin = UNERBUS_GetInt8(aBus);
		myWallValues.outputMax = UNERBUS_GetInt8(aBus);
		myWallValues.base = UNERBUS_GetInt8(aBus);
		break;
	case GET_PID_WALL_GAINS:
		buf[0] = myWallValues.Kp & 0xFF;
		buf[1] = (myWallValues.Kp >> 8) & 0xFF;

		buf[2] = myWallValues.Ki & 0xFF;
		buf[3] = (myWallValues.Ki >> 8) & 0xFF;

		buf[4] = myWallValues.Kd & 0xFF;
		buf[5] = (myWallValues.Kd >> 8) & 0xFF;

		buf[6] = myWallValues.outputMin;
		buf[7] = myWallValues.outputMax;
		buf[8] = myWallValues.base;

		UNERBUS_Write(aBus, buf, 9);
		length = 10;
		break;
	case SET_PID_STOP_GAINS:
		myStopValues.Kp = UNERBUS_GetUInt16(aBus);
		myStopValues.Ki = UNERBUS_GetUInt16(aBus);
		myStopValues.Kd = UNERBUS_GetUInt16(aBus);
		myStopValues.outputMin = UNERBUS_GetInt8(aBus);
		myStopValues.outputMax = UNERBUS_GetInt8(aBus);
		myStopValues.base = UNERBUS_GetInt8(aBus);
		break;
	case GET_PID_STOP_GAINS:
		buf[0] = myStopValues.Kp & 0xFF;
		buf[1] = (myStopValues.Kp >> 8) & 0xFF;

		buf[2] = myStopValues.Ki & 0xFF;
		buf[3] = (myStopValues.Ki >> 8) & 0xFF;

		buf[4] = myStopValues.Kd & 0xFF;
		buf[5] = (myStopValues.Kd >> 8) & 0xFF;

		buf[6] = myStopValues.outputMin;
		buf[7] = myStopValues.outputMax;
		buf[8] = myStopValues.base;

		UNERBUS_Write(aBus, buf, 9);
		length = 10;
		break;
	case SET_ROBOT_MODE:
		currentMode = UNERBUS_GetUInt8(aBus);

		if (currentMode == MODE_EXPLORING_MAZE) {
			Robot_ExploreMaze();
		}
		else if (currentMode == MODE_FINDING_MARKS) {
			Robot_StartFindingMarks(); // Llamamos a la nueva función
		}
		else if (currentMode == MODE_IDLE) {
			Robot_Stop();
		}
		break;
	case SET_MAZE_TARGET:
		currentPosition.targetX = UNERBUS_GetUInt8(aBus);
		currentPosition.targetY = UNERBUS_GetUInt8(aBus);
		break;
	case SET_MAZE_START:
		currentPosition.currentX = UNERBUS_GetUInt8(aBus);
		currentPosition.currentY = UNERBUS_GetUInt8(aBus);
		currentDirection = (Map_Direction_e)UNERBUS_GetUInt8(aBus);
		break;
	case GET_CURRENT_ACTION:

		break;
	case GET_INTERSECTION_TYPE:
		{
	    uint8_t frontWall = (PERCEPTION_FRONT_LEFT | PERCEPTION_FRONT_RIGHT);
	    uint8_t leftWall  = PERCEPTION_DIAG_LEFT;
	    uint8_t rightWall = PERCEPTION_DIAG_RIGHT;

	    uint8_t intersectionIndex = (leftWall << 2) | (frontWall << 1) | (rightWall);

	    UNERBUS_WriteByte(aBus, intersectionIndex);
	    length = 2;
		}
		break;
	case GET_MAP_INFO:

		break;
	}

	if(length)
		UNERBUS_Send(aBus, id, length);

}

void USBReceive(uint8_t *buf, uint16_t len){
	UNERBUS_ReceiveBuf(&unerbusPC, buf, len);
}

/////////////////////////////// PROGRAM FUNCTIONS ///////////////////////////////
void Do1ms(){
	on1MS = 0;

	if(t10MS)
		t10MS--;

	Infrared_DigitalPerception(&myInfraredValues, &flagsIR.byte);
}

void Do10ms(){
	t10MS = 10;

	if(t20MS)
		t20MS--;

	if(t100MS)
		t100MS--;

	Robot_StateMachine();

	MPU6050_Get_Yaw(&myMpuValues, 10);
	MPU_READ_REQUEST = 1;

	Infrared_Convert(&myInfraredValues);

	if (currentPage == DISPLAY_RUN) {
		if (currentAction == ACTION_TURN_PIVOT) {
			if (FILTERED_FRONT_UNDER_IR < LINE_DETECTION_THRESHOLD)
				LINE_DETECTED_TURNING = 1;
		} else if (currentAction != ACTION_CENTER_IN_CELL){
			Robot_CheckCellCrossing();
		}
	}

	ESP01_Timeout10ms();
	UNERBUS_Timeout(&unerbusESP01);
	UNERBUS_Timeout(&unerbusPC);

	ENGINE_Task(&myEngines);
}

void Do20ms(){
	t20MS = 2;
}

void Do100ms(){
	t100MS = 10;

	if(t1S)
		t1S--;

	Heartbeat();

	ChangeDisplayPage(currentPage);

	static uint8_t telemetryDivisor = 0;
	telemetryDivisor++;

	if (telemetryDivisor >= 2) { // 2 ejecuciones de 100ms = 200ms
		telemetryDivisor = 0; // Reiniciamos el contador

		if (currentMode == MODE_EXPLORING_MAZE || currentMode == MODE_FINDING_MARKS) {
			uint8_t buf[40];
			buf[0] = currentPosition.currentX;
			buf[1] = currentPosition.currentY;
			buf[2] = currentPosition.maze[currentPosition.currentX][currentPosition.currentY].walls;
			buf[3] = currentDirection;
			buf[4] = currentAction;       // Para saber en Qt si está pivotando, centrando, etc.
			buf[5] = cellState;           // Para saber si está en línea, adentro, etc.
			buf[6] = marksCount;          // Cuántas marcas lleva
			buf[7] = markDetected;        // 1 si está sobre una celda negra ahora mismo

			// --- 2. SENSORES IR (16 Bytes: [8] a [23]) ---
			for (uint8_t i = 0; i < 8; i++) {
				// En lugar de escribir a mano cada línea, un loop es más limpio
				buf[8 + (i * 2)] = myInfraredValues.filteredSamples[i] & 0xFF;
				buf[9 + (i * 2)] = (myInfraredValues.filteredSamples[i] >> 8) & 0xFF;
			}

			// --- 3. MOTORES (2 Bytes: [24] y [25]) ---
			buf[24] = myEngines.currentLeftSpeed;
			buf[25] = myEngines.currentRightSpeed;

			// --- 4. MPU6050  CRUDO (6 Bytes: [26] a [39]) ---
			MPU6050_Compose_Number(&myMpuValues, &buf[26]);

			// Enviamos el bloque entero de 40 bytes
			UNERBUS_Write(&unerbusESP01, buf, 40);
			UNERBUS_Send(&unerbusESP01, STREAM_TELEMETRY, 38);
		}
	}
	/*
	if(heartbeatmask & heartbeat)
		HAL_GPIO_WritePin(LED_GPIO_Port, LED_Pin, GPIO_PIN_RESET);
	else
		HAL_GPIO_WritePin(LED_GPIO_Port, LED_Pin, GPIO_PIN_SET);

	heartbeatmask >>= 1;
	if(!heartbeatmask)
		heartbeatmask = 0x80000000;
	*/

	if(tOutAliveUDP)
		tOutAliveUDP--;
}

void Do1s(void) {
	t1S = 10;
}

void Robot_StateMachine() {
//	switch(currentMode){
//	case MODE_IDLE:
//		//currentAction = ACTION_IDLE;
//		break;
//	case MODE_EXPLORING_MAZE:
////		Robot_ExploreMaze();
//		break;
//	case MODE_MAZE_RUNNER:
//		break;
//	case MODE_FINDING_MARKS:
//		break;
//	}

	switch(currentAction) {
	case ACTION_IDLE:
		ENGINE_SetLeftSpeed(&myEngines, 0);
		ENGINE_SetRightSpeed(&myEngines, 0);
		break;
	case ACTION_FOLLOW_WALL:
		Robot_FollowWall_Control();
		break;
	case ACTION_TURN_PIVOT:
		Robot_Turn_Control(pivotDegreesTarget);
		break;
	case ACTION_CENTER_IN_CELL:
		Robot_FollowWall_Control();

		if (!(detectedIntersection & 0b010)) { // Si no hay pared al frente
			if (HAL_GetTick() - centeringStartTime >= timeToCenter) {
				ENGINE_SetLeftSpeed(&myEngines, 0);
				ENGINE_SetRightSpeed(&myEngines, 0);

				currentAction = ACTION_TURN_PIVOT;

				PID_Reset(&myTurnValues);

				if (currentPosition.currentX == currentPosition.targetX && currentPosition.currentY == currentPosition.targetY) {
					Robot_Stop(); // Si era la meta, apagar en el centro exacto.
				} else {
					currentAction = ACTION_TURN_PIVOT; // Si no, seguir con el giro.
					PID_Reset(&myTurnValues);
				}
			}
		}

	    break;
	case ACTION_AFTER_TURN:
		Robot_FollowWall_Control();
		break;
	case ACTION_BACK_WALL_ALIGN:
	{
		// Usa EXCLUSIVAMENTE el giroscopio
		// para mantener la línea recta perfecta en reversa.
		int32_t errorGyro = myMpuValues.data.relativeYawScaled / YAW_SCALE;

		int32_t errorTotal = errorGyro * GYRO_COMPENSATION_GAIN;

		// Calcular la corrección usando el PID de reversa
		PID_Compute(&myReverseValues, errorTotal, 10);
		int8_t correction = (int8_t)myReverseValues.output;

		// Aplicamos la corrección a los motores.
		// La fórmula matemática para mantener el centro con el giroscopio
		// ya contempla la inversión de giro, por lo que los signos quedan igual.
		ENGINE_SetLeftSpeed(&myEngines, myReverseValues.base - correction);
		ENGINE_SetRightSpeed(&myEngines, myReverseValues.base + correction);

		// Esperamos el impacto (1450 ms).
		if (HAL_GetTick() - alignStartTime >= 1450) {
			ENGINE_SetLeftSpeed(&myEngines, 0);
			ENGINE_SetRightSpeed(&myEngines, 0);

			MPU6050_Reset_Yaw(&myMpuValues);
			currentAction = ACTION_AFTER_TURN;
		}
		break;
	}
	case ACTION_MOTOR_TEST:
		break;
	default:
		currentAction = ACTION_IDLE;
		break;
	}
}

void Robot_Stop(void) {
    // Frenar físicamente el robot
    ENGINE_SetLeftSpeed(&myEngines, 0);
    ENGINE_SetRightSpeed(&myEngines, 0);

    if (currentPosition.currentX == currentPosition.targetX && currentPosition.currentY == currentPosition.targetY) {
		currentPage = DISPLAY_END_SCREEN;
	} else {
		currentPage = DISPLAY_MENU;
	}

    // Resetear la máquina de estados lógicos
    currentMode = MODE_IDLE;
    currentAction = ACTION_IDLE;

    // Forzar la interfaz a volver al menú principal
    currentPage = DISPLAY_MENU;
    ChangeDisplayPage(DISPLAY_MENU);
}

void Robot_ExploreMaze(void) {
	currentMode = MODE_EXPLORING_MAZE;
	currentPage = DISPLAY_RUN;
	ChangeDisplayPage(DISPLAY_RUN);

	// --- INICIALIZACIÓN DEL MAPA ---
//	currentPosition.currentX = 0;
//	currentPosition.currentY = 0;
//	currentDirection = EAST;
	currentPosition.maze[currentPosition.currentX][currentPosition.currentY].visited = 1;

	// Forzamos las paredes de la esquina inicial (Oeste y Sur)
//	currentPosition.maze[0][0].walls |= (1 << WEST) | (1 << SOUTH) | (1 << NORTH);
	// -------------------------------
	uint8_t hasLeft = (FILTERED_LEFT_IR > 350) ? 1 : 0;
	uint8_t hasFront = (FILTERED_FRONT_LEFT_IR > 350 || FILTERED_FRONT_RIGHT_IR > 350) ? 1 : 0;
	uint8_t hasRight = (FILTERED_RIGHT_IR > 350) ? 1 : 0;

	Map_UpdateCell(hasLeft, hasFront, hasRight);

	Map_AddWallToMap(currentPosition.currentX, currentPosition.currentY, (currentDirection + 2) % 4);

	detectedIntersection = (IntersectionType_e)((hasLeft << 2) | (hasFront << 1) | hasRight);
	cellState = CELL_INSIDE_CELL;

	PID_Reset(&myWallValues);
	PID_Reset(&myTurnValues);
	PID_Reset(&myStopValues);
	MPU6050_Reset_Yaw(&myMpuValues);

	referenceLeftWall = 42;
	referenceRightWall = 42;

	if (currentPosition.currentX == currentPosition.targetX && currentPosition.currentY == currentPosition.targetY) {
		Robot_Stop(); // Ya estamos donde queremos ir
		return;
	}

	FloodFill_Calculate();

	int8_t nextTurn = Robot_CalculateNextMove();

	// 3. DECIDIR ACCIÓN INICIAL
	if (nextTurn != 0) {
		// El camino nos pide girar
		switch(nextTurn) {
			case 1: pivotDegreesTarget = -90; Map_UpdateDirection(1); break;
			case -1: pivotDegreesTarget = 90; Map_UpdateDirection(-1); break;
			case 2: pivotDegreesTarget = 180; Map_UpdateDirection(2); break;
		}
		currentAction = ACTION_TURN_PIVOT; // Girar sobre el eje sin avanzar
	} else {
		// El camino es recto, avanzar normal
		currentAction = ACTION_FOLLOW_WALL;
	}
}

void Robot_StartFindingMarks(void) {
    currentMode = MODE_FINDING_MARKS;
    currentPage = DISPLAY_RUN;
    ChangeDisplayPage(DISPLAY_RUN);

    referenceLeftWall = 42;
    referenceRightWall = 42;
    marksCount = 0; // Reiniciar contador

    currentPosition.maze[currentPosition.currentX][currentPosition.currentY].visited = 1;

    uint8_t hasLeft = (FILTERED_LEFT_IR > 350) ? 1 : 0;
	uint8_t hasFront = (FILTERED_FRONT_LEFT_IR > 350 || FILTERED_FRONT_RIGHT_IR > 350) ? 1 : 0;
	uint8_t hasRight = (FILTERED_RIGHT_IR > 350) ? 1 : 0;

	Map_UpdateCell(hasLeft, hasFront, hasRight);

	Map_AddWallToMap(currentPosition.currentX, currentPosition.currentY, (currentDirection + 2) % 4);

	detectedIntersection = (IntersectionType_e)((hasLeft << 2) | (hasFront << 1) | hasRight);

    cellState = CELL_INSIDE_CELL;

    PID_Reset(&myWallValues);
	PID_Reset(&myTurnValues);
	PID_Reset(&myStopValues);
	MPU6050_Reset_Yaw(&myMpuValues);

	// DEFINIR EL OBJETIVO (DOBLE LÓGICA)
	if (marksCount >= 3) {
		// LÓGICA A (RECORRIDO): Ya conoce las 3 marcas.
		currentMarkTargetIndex = 0;
		currentPosition.targetX = markLocations[currentMarkTargetIndex].x;
		currentPosition.targetY = markLocations[currentMarkTargetIndex].y;

		// ¿Ya estamos parados en la primera marca en la largada?
//		if (currentPosition.currentX == currentPosition.targetX && currentPosition.currentY == currentPosition.targetY) {
//			currentMarkTargetIndex++;
//			currentPosition.targetX = markLocations[currentMarkTargetIndex].x;
//			currentPosition.targetY = markLocations[currentMarkTargetIndex].y;
//		}
	} else {
		// LÓGICA B (BÚSQUEDA): Aún faltan marcas. Busca la celda no visitada más cercana.
		if (!Map_SetTargetToNearestUnvisited()) {
			Robot_Stop(); // Failsafe: Mapa explorado 100% pero no estaban las 3 marcas
			return;
		}
	}

	FloodFill_Calculate();
	int8_t nextTurn = Robot_CalculateNextMove();

	// DECIDIR ACCIÓN INICIAL
	if (nextTurn != 0) {
		// First move will be a turn if the target is not the front cell
		switch(nextTurn) {
			case 1: pivotDegreesTarget = -90; Map_UpdateDirection(1); break;
			case -1: pivotDegreesTarget = 90; Map_UpdateDirection(-1); break;
			case 2: pivotDegreesTarget = 180; Map_UpdateDirection(2); break;
		}
		currentAction = ACTION_TURN_PIVOT;
	} else {
		// The target is the first cell -> go straight
		currentAction = ACTION_FOLLOW_WALL;
	}
}

void Robot_FollowWall_Control(void) {
	uint8_t hasLeftWall;
	uint8_t hasRightWall;

	int32_t errorWall;
	int32_t errorGyro;
	int32_t errorTotal;
	int8_t correction;

	int32_t currentYaw = myMpuValues.data.relativeYawScaled;

	#define LATERAL_WALL_THRESHOLD_MM 80

	// Si el robot va por el pasillo, detecta en tiempo real las paredes a los costados
	// Si está en otra situación, se basa en la detección de la intersección para definir que paredes usar
	if (currentAction == ACTION_AFTER_TURN) {
		hasLeftWall = (DIST_LEFT_IR < 60) ? 1 : 0;
		hasRightWall = (DIST_RIGHT_IR < 60) ? 1 : 0;
	}
	else if (cellState == CELL_INSIDE_CELL && (currentAction == ACTION_FOLLOW_WALL)) {
		hasLeftWall = (DIST_LEFT_IR < LATERAL_WALL_THRESHOLD_MM) ? 1 : 0;
		hasRightWall = (DIST_RIGHT_IR < LATERAL_WALL_THRESHOLD_MM) ? 1 : 0;

		// FILTRO DE ANCHO DE PASILLO
		if (hasLeftWall && hasRightWall) {
			#define MAX_CORRIDOR_SUM_MM 115 // Suma máxima nominal (ej: 110 + 10mm de tolerancia)

			uint16_t corridorSum = DIST_LEFT_IR + DIST_RIGHT_IR;

			if (corridorSum > MAX_CORRIDOR_SUM_MM) {
				// Si ambas paredes ya están bastante lejos de la referencia (ej > 50mm)
				// significa que estamos en una intersección doble (T o Cruce +)
				if (DIST_LEFT_IR > 50 && DIST_RIGHT_IR > 50) {
					hasLeftWall = 0;
					hasRightWall = 0; // Desactivamos ambas, que el giroscopio mantenga el centro
				}
				// Si no, es una apertura simple
				else {
					if (DIST_LEFT_IR > DIST_RIGHT_IR) {
						hasLeftWall = 0;  // Se abrió la izquierda
					} else {
						hasRightWall = 0; // Se abrió la derecha
					}
				}
			}
		}
	} else {
		hasLeftWall = (detectedIntersection & 0b100) ? 1 : 0;
		hasRightWall = (detectedIntersection & 0b001) ? 1 : 0;
	}

	activeLeftWall = hasLeftWall;
	activeRightWall = hasRightWall;

	if (hasLeftWall && hasRightWall) {
		// Caso 1: Dos paredes. El error es la diferencia entre ellas.
		errorWall = DIST_RIGHT_IR - DIST_LEFT_IR;
		errorTotal = errorWall;
	} else if (hasRightWall) {
		// Caso 2: Solo pared derecha. El error es la diferencia con la distancia objetivo.
		// El signo negativo se aplicará a la corrección, no al error.
		errorWall = 2 * (DIST_RIGHT_IR - referenceRightWall);
		errorTotal = errorWall;
	} else if (hasLeftWall) {
		// Caso 3: Solo pared izquierda. El error es la diferencia con la distancia objetivo.
		errorWall = 2 * (referenceLeftWall - DIST_LEFT_IR);
		errorTotal = errorWall;
	} else {
		// Caso 4: sin paredes, navegar de forma ciega
		errorWall = 0;
		errorGyro = (currentYaw - wallFollowTargetYaw) / YAW_SCALE;
		errorTotal = errorGyro * GYRO_COMPENSATION_GAIN;
	}

	if (abs(errorTotal) > WALL_ERROR_DEADZONE) {
		PID_Compute(&myWallValues, errorTotal, 10);
		correction = (int8_t)myWallValues.output;
	} else {
		// Si estamos en la zona muerta o no hay paredes, no hay corrección.
		// Además, reseteamos el PID para evitar que el término integral acumulado
		// cause un salto brusco cuando volvamos a necesitarlo.
		PID_Reset(&myWallValues);
		correction = 0;
	}

	// INICIO PID FRENO
	int8_t currentBaseSpeed = myWallValues.base; // Guardamos la velocidad base original temporalmente

	// Tomamos el valor más bajo de los dos sensores frontales por seguridad
	uint16_t minFrontDist = (DIST_FRONT_LEFT_IR < DIST_FRONT_RIGHT_IR) ? DIST_FRONT_LEFT_IR : DIST_FRONT_RIGHT_IR;

	uint16_t brakeStartMm = 95; // Distancia a la que empezamos a soltar el acelerador
	uint16_t targetStopMm = 50;
	uint16_t stopToleranceMm = 5; // Distancia a la que cortamos (850 +/- 50)

	if ((detectedIntersection & 0b010) && (currentAction == ACTION_CENTER_IN_CELL)) {
		if (minFrontDist <= brakeStartMm) {
			// Calculamos el error.
			// Si maxFrontIR es 300 (lejos) -> errorDistance es +550
			// Si maxFrontIR es 900 (se pasó por inercia) -> errorDistance es -50
			int16_t errorDistance = minFrontDist - targetStopMm;

			PID_Compute(&myStopValues, errorDistance, 10);

			currentBaseSpeed = (int8_t)myStopValues.output;

			int8_t STOP_MIN_PWM = 30; // % mínimo que mueve al robot

			if (currentBaseSpeed > 0 && currentBaseSpeed < STOP_MIN_PWM) {
				currentBaseSpeed = STOP_MIN_PWM;
			} else if (currentBaseSpeed < 0 && currentBaseSpeed > -STOP_MIN_PWM) {
				currentBaseSpeed = -STOP_MIN_PWM; // Para que la reversa también tenga fuerza
			}

			// Si estamos dentro del rango objetivo, cortamos todo y salimos
			if (abs(errorDistance) <= stopToleranceMm) {
				ENGINE_SetLeftSpeed(&myEngines, 0);
				ENGINE_SetRightSpeed(&myEngines, 0);

				PID_Reset(&myStopValues);
				PID_Reset(&myWallValues);

				currentAction = ACTION_TURN_PIVOT;

				if (currentPosition.currentX == currentPosition.targetX && currentPosition.currentY == currentPosition.targetY) {
					Robot_Stop();
				} else {
					currentAction = ACTION_TURN_PIVOT;
				}
				return; // Abortar para no sobrescribir el 0
			}
		} else {
			PID_Reset(&myStopValues);
		}

	}

	ENGINE_SetLeftSpeed(&myEngines, (-currentBaseSpeed - correction));
	ENGINE_SetRightSpeed(&myEngines, (-currentBaseSpeed + correction));
}

void Robot_Turn_Control(int16_t degreesToTurn) {
	int32_t error = myMpuValues.data.relativeYawScaled - (degreesToTurn * YAW_SCALE);
	int32_t errorAbs = (error < 0) ? -error : error;

	if (errorAbs <= TURN_THRESHOLD) {
		ENGINE_SetLeftSpeed(&myEngines, 0);
		ENGINE_SetRightSpeed(&myEngines, 0);

		uint8_t pathBlocked = ((DIST_FRONT_LEFT_IR < 80) || (DIST_FRONT_RIGHT_IR < 80));

		if (pathBlocked) {
			if (degreesToTurn > 0) {
				pivotDegreesTarget += 90;
				Map_UpdateDirection(-1);
			} else {
				pivotDegreesTarget -= 90;
				Map_UpdateDirection(1);
			}

			return;
		}

		uint8_t wallBehind = 0;

		if (degreesToTurn == 180 || degreesToTurn == -180) {
			// En un giro de 180°, la pared que queda atrás es la que estaba ENFRENTE (0b010)
			if (detectedIntersection & 0b010) wallBehind = 1;
		}
		else if (degreesToTurn > 0) { // Giro a la izquierda (+90)
			// La pared que queda atrás es la DERECHA original (0b001)
			if (detectedIntersection & 0b001) wallBehind = 1;
		}
		else if (degreesToTurn < 0) { // Giro a la derecha (-90)
			// La pared que queda atrás es la IZQUIERDA original (0b100)
			if (detectedIntersection & 0b100) wallBehind = 1;
		}

		if (wallBehind) {
			currentAction = ACTION_BACK_WALL_ALIGN;
			alignStartTime = HAL_GetTick();
		} else {
			currentAction = ACTION_AFTER_TURN;
		}

		PID_Reset(&myWallValues);
		PID_Reset(&myTurnValues);
		MPU6050_Reset_Yaw(&myMpuValues);

		if (markDetected)
			cellState = CELL_REAR_LINE;
		else
			cellState = CELL_INSIDE_CELL;

		wallFollowTargetYaw = 0;

		return;
	}

	PID_Compute_Gyro(&myTurnValues, error, myMpuValues.data.gyroZ);
//	PID_Compute(&myTurnValues, error, 10);

	int8_t power = (int8_t)myTurnValues.output;
	if (errorAbs > (15 * YAW_SCALE)) {
		if (power > 0 && power < TURN_MIN_PWM) power = TURN_MIN_PWM;
		else if (power < 0 && power > -TURN_MIN_PWM) power = -TURN_MIN_PWM;
	}

	ENGINE_SetLeftSpeed(&myEngines, -power);
	ENGINE_SetRightSpeed(&myEngines, power);
}

IntersectionType_e Robot_IdentifyIntersection(void) {
    // Determinar el estado de las paredes
    uint8_t frontWall = (PERCEPTION_FRONT_LEFT | PERCEPTION_FRONT_RIGHT);
    uint8_t leftWall  = PERCEPTION_DIAG_LEFT;
    uint8_t rightWall = PERCEPTION_DIAG_RIGHT;

    // Combinar los estados en un índice de 3 bits
    uint8_t intersectionIndex = (leftWall << 2) | (frontWall << 1) | (rightWall);

    // Devolver el resultado directamente desde la tabla
    return (IntersectionType_e)intersectionIndex;
//    return intersectionLUT[intersectionIndex];
}

void Robot_CheckCellCrossing(void) {
	#define WALL_PRESENCE_THR 350 // Si es menor a 150mm, hay pared.
	#define WALL_PRESENCE_THR_MM 100

	uint8_t frontLine = (FILTERED_FRONT_UNDER_IR < LINE_DETECTION_THRESHOLD);
    uint8_t rearLine  = (FILTERED_REAR_UNDER_IR < LINE_DETECTION_THRESHOLD);

    static int8_t earlyIntersection = 0;

    switch (cellState) {
        case CELL_INSIDE_CELL:
            if (frontLine) { 		// Wait until the front sensor see the line

            	myVelocity.time_frontLineDetect = HAL_GetTick();

                cellState = CELL_FRONT_LINE;

                earlyIntersection = 0;
                earlyIntersection = ((FILTERED_DIAG_LEFT_IR > LEFT_DIAG_THR_RAW) << 2) | (FILTERED_DIAG_RIGHT_IR > RIGHT_DIAG_THR_RAW);

                detectedIntersection = (IntersectionType_e)earlyIntersection;
            } else if (rearLine) { // Failsafe
            	uint8_t hasFrontWall = (FILTERED_FRONT_LEFT_IR > 350 || FILTERED_FRONT_RIGHT_IR > 350) ? 1 : 0;
				uint8_t hasLeftWall = (FILTERED_LEFT_IR > 100) ? 1 : 0;
				uint8_t hasRightWall = (FILTERED_RIGHT_IR > 100) ? 1 : 0;

				detectedIntersection = (IntersectionType_e)((hasLeftWall << 2) | (hasFrontWall << 1) | hasRightWall);

				// 3. Actualizamos el mapa
				Map_UpdateCoordinates();
				Map_UpdateCell(hasLeftWall, hasFrontWall, hasRightWall);

				if (currentMode == MODE_EXPLORING_MAZE) {
					if (currentPosition.currentX == currentPosition.targetX && currentPosition.currentY == currentPosition.targetY) {
						pivotDegreesTarget = 0;
					} else {
						FloodFill_Calculate();
						int8_t nextTurn = Robot_CalculateNextMove();

						switch(nextTurn) {
							case 0: pivotDegreesTarget = 0; break;
							case 1: pivotDegreesTarget = -90; Map_UpdateDirection(1); break;
							case -1: pivotDegreesTarget = 90; Map_UpdateDirection(-1); break;
							case 2: pivotDegreesTarget = 180; Map_UpdateDirection(2); break;
						}
					}
				}

				// 4. Saltamos directamente al estado trasero
				cellState = CELL_REAR_LINE;

				// 5. Disparamos la acción de centrado
				if (pivotDegreesTarget != 0 || (currentPosition.currentX == currentPosition.targetX && currentPosition.currentY == currentPosition.targetY)) {
					currentAction = ACTION_CENTER_IN_CELL;
					centeringStartTime = HAL_GetTick();
					timeToCenter = 250; // Tu tiempo de rescate estimado
				}
            }
            break;
        case CELL_FRONT_LINE:
            if (!frontLine) {

            }

            if (rearLine) {
            	myVelocity.time_rearLineDetect = HAL_GetTick();
            	myVelocity.time_dt_ms = myVelocity.time_rearLineDetect - myVelocity.time_frontLineDetect;

            	myVelocity.currentVelocity_mm_s = (DISTANCE_FRONT_TO_REAR_IR * 1000) / myVelocity.time_dt_ms;
            	Map_UpdateCoordinates();

                if (frontLine) {
                	markDetected = 1;
                	myVelocity.time_frontLineLost = 0;
                	// Mark detected
//                	Map_UpdateCoordinates();
                	Mark_SaveLocation(currentPosition.currentX, currentPosition.currentY);

                	uint8_t cx = currentPosition.currentX;
					uint8_t cy = currentPosition.currentY;
					UNERBUS_WriteByte(&unerbusESP01, cx);
					UNERBUS_WriteByte(&unerbusESP01, cy);
					UNERBUS_WriteByte(&unerbusESP01, currentPosition.maze[cx][cy].walls);
					UNERBUS_WriteByte(&unerbusESP01, currentDirection);
					UNERBUS_Send(&unerbusESP01, GET_MAP_INFO, 5);

                	if (currentMode == MODE_FINDING_MARKS && marksCount >= 3) {
                		Robot_Stop();
                		ChangeDisplayPage(DISPLAY_RUN);
                		return;
                	}
                } else {
                	markDetected = 0;

                }

            	// 1. Evaluar paredes
				uint8_t hasFrontWall = (FILTERED_FRONT_LEFT_IR > WALL_PRESENCE_THR || FILTERED_FRONT_RIGHT_IR > WALL_PRESENCE_THR) ? 1 : 0;
				uint8_t hasLeftWall = (FILTERED_LEFT_IR > WALL_PRESENCE_THR) ? 1 : 0;
				uint8_t hasRightWall = (FILTERED_RIGHT_IR > WALL_PRESENCE_THR) ? 1 : 0;

				Robot_ProcessIntersection(hasLeftWall, hasFrontWall, hasRightWall);

                cellState = CELL_REAR_LINE;

            	if (currentAction == ACTION_AFTER_TURN){
            		currentAction = ACTION_FOLLOW_WALL;
            	}
            }
            break;
        case CELL_REAR_LINE:
			if (markDetected && !frontLine && myVelocity.time_frontLineLost == 0) {
				myVelocity.time_frontLineLost = HAL_GetTick();

                earlyIntersection = 0;
                earlyIntersection = ((FILTERED_DIAG_LEFT_IR > LEFT_DIAG_THR_RAW) << 2) | (FILTERED_DIAG_RIGHT_IR > RIGHT_DIAG_THR_RAW);

                detectedIntersection = (IntersectionType_e)earlyIntersection;
			}

			if (!rearLine) {
				// Si veníamos de una celda negra, este borde (Negro -> Blanco)
				// actúa como la línea de entrada para la SIGUIENTE celda.
				if (markDetected) {
					myVelocity.time_rearLineLost = HAL_GetTick();

					if (myVelocity.time_frontLineLost != 0) {
						uint32_t dt_exit = myVelocity.time_rearLineLost - myVelocity.time_frontLineLost;
						if (dt_exit > 0) {
							myVelocity.currentVelocity_mm_s = (DISTANCE_FRONT_TO_REAR_IR * 1000) / dt_exit;
						}
					}

					Map_UpdateCoordinates();

					// Leemos las paredes de la nueva celda
					uint8_t hasFrontWall = (FILTERED_FRONT_LEFT_IR > WALL_PRESENCE_THR || FILTERED_FRONT_RIGHT_IR > WALL_PRESENCE_THR) ? 1 : 0;
					uint8_t hasLeftWall = (FILTERED_LEFT_IR > WALL_PRESENCE_THR) ? 1 : 0;
					uint8_t hasRightWall = (FILTERED_RIGHT_IR > WALL_PRESENCE_THR) ? 1 : 0;

					Robot_ProcessIntersection(hasLeftWall, hasFrontWall, hasRightWall);

					// Apagamos la bandera para que la siguiente celda sea normal
					markDetected = 0;
					cellState = CELL_CROSS_FINISHED;
				} else {
					if (currentAction == ACTION_FOLLOW_WALL) //|| currentAction == ACTION_AFTER_TURN)
						cellState = CELL_CROSS_FINISHED;
				}

			}

            break;
        case CELL_CROSS_FINISHED:
            // NEW CELL CONFIRMED

            // Return to initial state
            cellState = CELL_INSIDE_CELL;
            break;
    }
}

void Robot_ProcessIntersection(uint8_t hasLeftWall, uint8_t hasFrontWall, uint8_t hasRightWall) {
    // Guardar la intersección
    detectedIntersection = (IntersectionType_e)((hasLeftWall << 2) | (hasFrontWall << 1) | hasRightWall);

    // Actualizar mapa
    Map_UpdateCell(hasLeftWall, hasFrontWall, hasRightWall);

    // Calcular siguiente movimiento (FloodFill)
    if (currentMode == MODE_EXPLORING_MAZE) {
    	// Verify if the robot reached the end
        if (currentPosition.currentX == currentPosition.targetX && currentPosition.currentY == currentPosition.targetY) {
            pivotDegreesTarget = 0;
        } else {
		// If not, recalculate the map and decide the next move
            FloodFill_Calculate();
            int8_t nextTurn = Robot_CalculateNextMove();

            switch(nextTurn) {
                case 0: pivotDegreesTarget = 0; break;
                case 1: pivotDegreesTarget = -90; Map_UpdateDirection(1); break;
                case -1: pivotDegreesTarget = 90; Map_UpdateDirection(-1); break;
                case 2: pivotDegreesTarget = 180; Map_UpdateDirection(2); break;
            }
        }
    } else if (currentMode == MODE_FINDING_MARKS) {
    	// 1. Condición de victoria: ¿Ya encontró las 3?
		if (marksCount >= 3) {
			// --- LÓGICA A (RECORRIDO SECUENCIAL) ---
			if (currentPosition.currentX == currentPosition.targetX && currentPosition.currentY == currentPosition.targetY) {
				currentMarkTargetIndex++; // Pasamos a la siguiente marca

				if (currentMarkTargetIndex >= 3) {
					pivotDegreesTarget = 0;
					Robot_Stop();
				} else {
					currentPosition.targetX = markLocations[currentMarkTargetIndex].x;
					currentPosition.targetY = markLocations[currentMarkTargetIndex].y;
				}
			}
//			pivotDegreesTarget = 0;
//			Robot_Stop();
		} else {
			// ¿Llegó a la celda que estaba yendo a explorar?
			if (currentPosition.currentX == currentPosition.targetX && currentPosition.currentY == currentPosition.targetY) {
				// Buscamos una NUEVA celda en la niebla para setear como Target
				if (!Map_SetTargetToNearestUnvisited()) {
					pivotDegreesTarget = 0;
					Robot_Stop(); // Error: El laberinto se exploró al 100% y no había 3 marcas
				}
			}

			// Ya sea que mantenga el target anterior o le hayamos dado uno nuevo, calculamos la ruta:
			if (currentMode == MODE_FINDING_MARKS) {
				FloodFill_Calculate();
				int8_t nextTurn = Robot_CalculateNextMove();
				switch(nextTurn) {
					case 0: pivotDegreesTarget = 0; break;
					case 1: pivotDegreesTarget = -90; Map_UpdateDirection(1); break;
					case -1: pivotDegreesTarget = 90; Map_UpdateDirection(-1); break;
					case 2: pivotDegreesTarget = 180; Map_UpdateDirection(2); break;
				}
			}
		}
    }

    // Crear una bandera local para saber si estamos en la celda final
    uint8_t isTarget = (currentPosition.currentX == currentPosition.targetX && currentPosition.currentY == currentPosition.targetY);

    // Disparar la acción de centrado si es necesario
    if (pivotDegreesTarget != 0 || isTarget) {
    	uint8_t distanceToCenter = 40;

        if (markDetected) {
			distanceToCenter = 50;
		}

        timeToCenter = (distanceToCenter * 1000) / myVelocity.currentVelocity_mm_s;
        currentAction = ACTION_CENTER_IN_CELL;
        centeringStartTime = HAL_GetTick();
    }
}

void Mark_SaveLocation(uint8_t x, uint8_t y) {
    // Si ya encontramos las 3, no hacemos nada extra
    if (marksCount >= 3) return;

    // Revisar si esta marca ya la habíamos encontrado antes (Filtro Anti-Duplicados)
    for (uint8_t i = 0; i < marksCount; i++) {
        if (markLocations[i].x == x && markLocations[i].y == y) {
            return; // Ya la tenemos registrada, abortamos
        }
    }

    // Es una marca nueva. La guardamos en el índice correspondiente.
    markLocations[marksCount].x = x;
    markLocations[marksCount].y = y;
    marksCount++;

    UNERBUS_WriteByte(&unerbusESP01, x);
	UNERBUS_WriteByte(&unerbusESP01, y);
	UNERBUS_WriteByte(&unerbusESP01, marksCount); // Enviamos el progreso (1/3, 2/3, etc)
	UNERBUS_Send(&unerbusESP01, GET_SPECIAL_CELL, 4); // 0xE5
}

uint8_t Map_SetTargetToNearestUnvisited(void) {
    if (currentPosition.maze[currentPosition.currentX][currentPosition.currentY].visited == 0) {
        currentPosition.targetX = currentPosition.currentX;
        currentPosition.targetY = currentPosition.currentY;
        return 1;
    }

    Point_s queue[64];
    uint16_t head = 0, tail = 0;
    uint8_t scanned[8][8] = {0};

    queue[tail].x = currentPosition.currentX;
    queue[tail].y = currentPosition.currentY;
    scanned[currentPosition.currentX][currentPosition.currentY] = 1;
    tail++;

    while (head < tail) {
        uint8_t cx = queue[head].x;
        uint8_t cy = queue[head].y;
        head++;

        if (currentPosition.maze[cx][cy].visited == 0) {
            currentPosition.targetX = cx;
            currentPosition.targetY = cy;
            return 1;
        }

        uint8_t walls = currentPosition.maze[cx][cy].walls;

        if (!(walls & (1 << NORTH)) && cy < 7 && !scanned[cx][cy+1]) {
            scanned[cx][cy+1] = 1; queue[tail].x = cx; queue[tail].y = cy + 1; tail++;
        }
        if (!(walls & (1 << EAST)) && cx < 7 && !scanned[cx+1][cy]) {
            scanned[cx+1][cy] = 1; queue[tail].x = cx + 1; queue[tail].y = cy; tail++;
        }
        if (!(walls & (1 << SOUTH)) && cy > 0 && !scanned[cx][cy-1]) {
            scanned[cx][cy-1] = 1; queue[tail].x = cx; queue[tail].y = cy - 1; tail++;
        }
        if (!(walls & (1 << WEST)) && cx > 0 && !scanned[cx-1][cy]) {
            scanned[cx-1][cy] = 1; queue[tail].x = cx - 1; queue[tail].y = cy; tail++;
        }
    }
    return 0; // Todo explorado
}

void FloodFill_Calculate(void) {
    // Reiniciamos los costos a 255
    for (uint8_t x = 0; x < 8; x++) {
        for (uint8_t y = 0; y < 8; y++) {
            currentPosition.maze[x][y].cost = 255;
        }
    }

    // Cola para el BFS
    Point_s queue[64];
    uint16_t head = 0;
    uint16_t tail = 0;

    // Establecemos la meta y la encolamos
    currentPosition.maze[currentPosition.targetX][currentPosition.targetY].cost = 0;
    queue[tail].x = currentPosition.targetX;
    queue[tail].y = currentPosition.targetY;
    tail++;

    // Inundación
    while (head < tail) {
        uint8_t cx = queue[head].x;
        uint8_t cy = queue[head].y;
        head++;

        uint8_t currentCost = currentPosition.maze[cx][cy].cost;
        uint8_t walls = currentPosition.maze[cx][cy].walls;

        // NORTE
        if (!(walls & (1 << NORTH)) && cy < 7) {
            if (currentPosition.maze[cx][cy+1].cost == 255) {
                currentPosition.maze[cx][cy+1].cost = currentCost + 1;
                queue[tail].x = cx;
                queue[tail].y = cy + 1;
                tail++;
            }
        }
        // ESTE
        if (!(walls & (1 << EAST)) && cx < 7) {
            if (currentPosition.maze[cx+1][cy].cost == 255) {
                currentPosition.maze[cx+1][cy].cost = currentCost + 1;
                queue[tail].x = cx + 1;
                queue[tail].y = cy;
                tail++;
            }
        }
        // SUR
        if (!(walls & (1 << SOUTH)) && cy > 0) {
            if (currentPosition.maze[cx][cy-1].cost == 255) {
                currentPosition.maze[cx][cy-1].cost = currentCost + 1;
                queue[tail].x = cx;
                queue[tail].y = cy - 1;
                tail++;
            }
        }
        // OESTE
        if (!(walls & (1 << WEST)) && cx > 0) {
            if (currentPosition.maze[cx-1][cy].cost == 255) {
                currentPosition.maze[cx-1][cy].cost = currentCost + 1;
                queue[tail].x = cx - 1;
                queue[tail].y = cy;
                tail++;
            }
        }
    }
}

int8_t Robot_CalculateNextMove(void) {
    uint8_t cx = currentPosition.currentX;
    uint8_t cy = currentPosition.currentY;
    uint8_t walls = currentPosition.maze[cx][cy].walls;

    uint8_t minCost = 255;
    Map_Direction_e bestAbsoluteDir = currentDirection;
    uint8_t foundUnvisited = 0;

    // Prioridad de exploración relativa: 0=Derecho, 1=Derecha, 3=Izquierda, 2=Atrás
    uint8_t dirOffsets[4] = {0, 1, 3, 2};

    for (int i = 0; i < 4; i++) {
        uint8_t absDir = (currentDirection + dirOffsets[i]) % 4;

        // Si no hay pared en esa dirección
        if (!(walls & (1 << absDir))) {
            uint8_t nx = cx, ny = cy;
            if (absDir == NORTH) ny++;
            else if (absDir == EAST) nx++;
            else if (absDir == SOUTH) ny--;
            else if (absDir == WEST) nx--;

            if (nx > 7 || ny > 7) continue; // Seguridad

            uint8_t neighborCost = currentPosition.maze[nx][ny].cost;
            uint8_t isUnvisited = (currentPosition.maze[nx][ny].visited == 0);

            uint8_t isBetter = 0;

            // Buscamos siempre el costo menor
            if (neighborCost < minCost) {
                isBetter = 1;
            }
            // En caso de EMPATE de costos, priorizamos las celdas no visitadas
            else if (neighborCost == minCost) {
                if (isUnvisited && !foundUnvisited) {
                    isBetter = 1;
                }
            }

            if (isBetter) {
                minCost = neighborCost;
                bestAbsoluteDir = (Map_Direction_e)absDir;
                foundUnvisited = isUnvisited;
            }
        }
    }

    // Calculamos el giro relativo a los motores
    int8_t relativeTurn = bestAbsoluteDir - currentDirection;
    if (relativeTurn > 2) relativeTurn -= 4;
    else if (relativeTurn < -2) relativeTurn += 4;

    if (relativeTurn == -2) relativeTurn = 2; // Normalizamos el 180 grados

    // Devuelve: 0 (Derecho), 1 (Derecha), -1 (Izquierda), 2 (Vuelta en U)
    return relativeTurn;
}

void Map_AddWallToMap(uint8_t x, uint8_t y, uint8_t dir) {
    // Pared en la celda actual
    currentPosition.maze[x][y].walls |= (1 << dir);

    // Pared espejada en la celda vecina (para que el Flood Fill no intente cruzar)
    if (dir == 0 && y < 7) currentPosition.maze[x][y+1].walls |= (1 << 2); // Norte -> Vecino Sur
    if (dir == 1 && x < 7) currentPosition.maze[x+1][y].walls |= (1 << 3); // Este -> Vecino Oeste
    if (dir == 2 && y > 0)  currentPosition.maze[x][y-1].walls |= (1 << 0); // Sur -> Vecino Norte
    if (dir == 3 && x > 0)  currentPosition.maze[x-1][y].walls |= (1 << 1); // Oeste -> Vecino Este
}

void Map_UpdateCell(uint8_t leftWall, uint8_t frontWall, uint8_t rightWall) {
	uint8_t dir;
	uint8_t buf[5];

	uint8_t x = currentPosition.currentX;
	uint8_t y = currentPosition.currentY;

	if (rightWall) {
		dir = (currentDirection + 1) % 4;
		Map_AddWallToMap(x, y, dir);
	}

	if (leftWall) {
		dir = (currentDirection + 3) % 4;
		Map_AddWallToMap(x, y, dir);
	}

	if ((frontWall)) {
		dir = (currentDirection + 0) % 4;
		Map_AddWallToMap(x, y, dir);
	}

	currentPosition.maze[x][y].visited = 1;

	buf[0] = x;
	buf[1] = y;
	buf[2] = currentPosition.maze[x][y].walls;
	buf[3] = currentDirection;

    UNERBUS_WriteByte(&unerbusESP01, buf[0]);
    UNERBUS_WriteByte(&unerbusESP01, buf[1]);
    UNERBUS_WriteByte(&unerbusESP01, buf[2]);
    UNERBUS_WriteByte(&unerbusESP01, buf[3]);
    UNERBUS_Send(&unerbusESP01, GET_MAP_INFO, 5);
}

void Map_UpdateDirection(int8_t turnDir) {
	// La aritmética de punteros con el enum Map_Direction_e:
	// NORTH=0, EAST=1, SOUTH=2, WEST=3

	// turn: 0 (Recto), 1 (Derecha +90), -1 (Izquierda -90), 2 (Media vuelta 180)

	int8_t newDir = currentDirection + turnDir;

	// Normalizar para mantenerlo entre 0 y 3
	if (newDir > 3) newDir -= 4;
	else if (newDir < 0) newDir += 4;

	currentDirection = (Map_Direction_e)newDir;
}

void Map_UpdateCoordinates(void) {
	switch(currentDirection){
		case NORTH:
			if(currentPosition.currentY < 7) currentPosition.currentY++;
			// Asumiendo (0,0) abajo-izquierda
			break;
		case EAST:
			if(currentPosition.currentX < 7) currentPosition.currentX++;
			break;
		case SOUTH:
			if(currentPosition.currentY > 0) currentPosition.currentY--;
			break;
		case WEST:
			if(currentPosition.currentX > 0) currentPosition.currentX--;
			break;
	}
}

void DrawRobotEyes(OLED_Handle_s *handle, IntersectionType_e intersection, Robot_Action_e action, int16_t turnTarget) {
    uint8_t baseW = 23, baseH = 34;
    uint8_t baseX_L = 34, baseX_R = 71;
    uint8_t baseY = 15;

    // Variables dinámicas
    uint8_t w_L = baseW, h_L = baseH;
    uint8_t w_R = baseW, h_R = baseH;
    uint8_t x_L = baseX_L, y_L = baseY;
    uint8_t x_R = baseX_R, y_R = baseY;

    uint8_t showEyebrow = 0;

    static uint32_t lastBlinkTime = 0;
	static uint8_t isBlinking = 0;
	static uint32_t nextBlinkInterval = 3500; // Inicia en 3 segundos

	uint32_t currentTick = HAL_GetTick();

	if (!isBlinking && (currentTick - lastBlinkTime > nextBlinkInterval)) {
		isBlinking = 1;
		lastBlinkTime = currentTick;
	}

	if (isBlinking) {
		if (currentTick - lastBlinkTime < 150) { // El parpadeo dura 150ms
			h_L = 4; h_R = 4;
			y_L = baseY + 15; // Cierra los ojos hacia el centro
			y_R = baseY + 15;
		} else {
			isBlinking = 0;
			lastBlinkTime = currentTick;
			// Aleatoriedad orgánica: el próximo parpadeo será entre 2 y 4.5 segundos
			nextBlinkInterval = 2000 + (currentTick % 2500);
		}
	}

	// 3. Expresiones según el estado (Solo aplican si NO está parpadeando)
//	if (!isBlinking) {
//		if (action == ACTION_TURN_PIVOT) {
//			// Acción: Girando -> Mira hacia el lado del giro por anticipación
//			if (turnTarget > 0) { // Girando a la izquierda
//				x_L = 1; x_R = 41;
//				y_L = 10; w_L = 26; h_L = 42; // Efecto de perspectiva (ojo más finito)
//			} else { // Girando a la derecha
//				x_L = 64; x_R = 101;
//				w_R = 26; y_R = 10; h_R = 42;
//			}
//		} else if (action == ACTION_BACK_WALL_ALIGN) {
//			// Acción: Retrocediendo/Alineándose -> Ojos chiquitos, como de precaución/susto
//			w_L = 14; h_L = 16; y_L = baseY + 8;
//			w_R = 14; h_R = 16; y_R = baseY + 8;
//		} else {
//			// Acción: Avanzando/Explorando -> Reacciona a lo que ve enfrente
//			switch(intersection) {
//				case INTERSECTION_DEAD_END:
//					// Sorprendido al ver un callejón sin salida (ojos más redondos)
//					w_L = 13; h_L = 15; y_L = baseY + 10;
//					break;
//				case INTERSECTION_CROSSROAD:
//				case INTERSECTION_T_ROAD:
//					// Concentrado, evaluando qué camino tomar (Cejas fruncidas)
//					showEyebrow = 1;
//					y_L = baseY + 10;
//					y_R = baseY + 10;
//					break;
//				case INTERSECTION_RIGHT_SQUARE:
//				case INTERSECTION_RIGHT_FRONT_OPEN:
//					// Mira de reojo a la derecha (viendo el hueco de la pared)
//					x_L = 1;
//					x_R = 41;
//					y_L = 10;
//					w_L = 26;
//					h_L = 42;
//					break;
//				case INTERSECTION_LEFT_SQUARE:
//				case INTERSECTION_LEFT_FRONT_OPEN:
//					// Mira de reojo a la izquierda
//					x_L = 64;
//					x_R = 101;
//					y_R = 10;
//					h_R = 42;
//					w_R = 26;
//					break;
//				default:
//					// INTERSECTION_UNKNOWN (Pasillo normal) usa los valores base
//					break;
//			}
//		}
//	}

	// 4. Dibujar los ojos en el buffer
	OLED_DrawDigitalEye(handle, x_L, y_L, w_L, h_L);
	OLED_DrawDigitalEye(handle, x_R, y_R, w_R, h_R);

	// 5. Dibujar cejas de "concentración" ( > < )
	if (showEyebrow && !isBlinking) {
		for(uint8_t i = 0; i < w_R - 5; i++) {
			uint8_t pixelsToErase = 9 - (i / 2);
			OLED_DrawVerticalLine(handle, x_R + i, y_R, pixelsToErase, Black);
		}
	}
}

void ChangeDisplayPage(DisplayPage_e page){
	const char* currentTitle = "";
	uint8_t y = GUI_HEADER_HEIGHT + GUI_WIDGET_ROW_GAP;
	char str[32];

	switch(page){
		case DISPLAY_CLEAR:
			OLED_Fill(&myOled, Black);
			break;
		case DISPLAY_MENU:
			currentTitle = "Menu";
			OLED_Fill(&myOled, Black);

			if (currentSelection >= scrollOffset + MAX_VISIBLE_ITEMS) {
			        scrollOffset = currentSelection - MAX_VISIBLE_ITEMS + 1;
			    }
			    // Si la selección subió por encima del scroll, subimos el scroll
			    if (currentSelection < scrollOffset) {
			        scrollOffset = currentSelection;
			    }

			    // DIBUJAR LISTA DE OPCIONES
			    for (int i = 0; i < MAX_VISIBLE_ITEMS; i++) {
			        int8_t itemIndex = scrollOffset + i;

			        if (itemIndex >= totalMenuItems) break; // No hay más items

			        int y_pos = MENU_START_Y + (i * MENU_ITEM_HEIGHT);

			        // ¿Es esta la opción seleccionada? -> DIBUJO INVERTIDO
			        if (itemIndex == currentSelection) {
			            // Dibuja un rectángulo blanco de fondo para la selección
			            OLED_DrawFilledRect(&myOled, 15, y_pos - 1, 98, MENU_ITEM_HEIGHT-1, White);

			            // Escribe el texto en NEGRO
			            OLED_SetCursor(&myOled, 15, y_pos);
			            sprintf(strAux, "%s", menuItems[itemIndex]);
			            OLED_WriteString(&myOled, strAux, Font_7x10, Black);
			        }
			        else {
			            // Opción normal (Fondo negro, texto blanco)
			        	//OLED_DrawRect(&myOled, 15, y_pos - 1, 98, MENU_ITEM_HEIGHT-1, Black);
			            OLED_SetCursor(&myOled, 15, y_pos);
			            sprintf(strAux, "%s", menuItems[itemIndex]);
			            OLED_WriteString(&myOled, strAux, Font_7x10, White);
			        }
			    }
			break;
		case DISPLAY_RUN_MODE_SELECT:
			currentTitle = "Select Mode";
			OLED_Fill(&myOled, Black);

			int y_pos_explore = MENU_START_Y;
			int y_pos_marks = MENU_START_Y + MENU_ITEM_HEIGHT;

			if (selectedRunMode == MODE_EXPLORING_MAZE) {
				// Resaltar Explore
				OLED_DrawFilledRect(&myOled, 15, y_pos_explore - 1, 98, MENU_ITEM_HEIGHT - 1, White);
				OLED_SetCursor(&myOled, 15, y_pos_explore);
				OLED_WriteString(&myOled, "Explore Maze", Font_7x10, Black);

				// Find Marks normal
				OLED_SetCursor(&myOled, 15, y_pos_marks);
				OLED_WriteString(&myOled, "Find Marks", Font_7x10, White);
			} else {
				// Explore normal
				OLED_SetCursor(&myOled, 15, y_pos_explore);
				OLED_WriteString(&myOled, "Explore Maze", Font_7x10, White);

				// Resaltar Find Marks
				OLED_DrawFilledRect(&myOled, 15, y_pos_marks - 1, 98, MENU_ITEM_HEIGHT - 1, White);
				OLED_SetCursor(&myOled, 15, y_pos_marks);
				OLED_WriteString(&myOled, "Find Marks", Font_7x10, Black);
			}
			break;
		case DISPLAY_RUN:
			/////////////////////////////////////////////////// DEBUG
			OLED_Fill(&myOled, Black);
			if (SHOW_EYES_SCREEN) {
				if (markDetected && currentMode == MODE_FINDING_MARKS) {
					OLED_Fill(&myOled, Black);
					sprintf(str, "MARK %d", marksCount);
					OLED_SetCursor(&myOled, 16, 19);
					OLED_WriteString(&myOled, str, Font_16x26, White);
					break; //Evita que dibuje el resto de la interfaz de RUN
				}

				OLED_Fill(&myOled, Black);
				int y_pos = MENU_START_Y + (MENU_ITEM_HEIGHT);
				OLED_SetCursor(&myOled, 1, y_pos-26);
				switch(currentAction) {
				case ACTION_IDLE:
					sprintf(str, "IDLE");
					break;
				case ACTION_FOLLOW_WALL:
					sprintf(str, "FOLLOW WALL");
					break;
				case ACTION_CENTER_IN_CELL:
					sprintf(str, "CENTER CELL");
					break;
				case ACTION_AFTER_TURN:
					sprintf(str, "AFTER TURN");
					break;
				case ACTION_TURN_PIVOT:
					sprintf(str, "PIVOT");
					break;
				case ACTION_BACK_WALL_ALIGN:
					sprintf(str, "ALIGN");
					break;
				default:
					break;
				}
				OLED_WriteString(&myOled, str, Font_7x10, White);

				OLED_SetCursor(&myOled, 1, y_pos-12);

				if(markDetected) {
					sprintf(str, "MARK | %d ", marksCount);
				} else {
					sprintf(str, "NO MARK   ");
				}

	//			int32_t currentYaw = myMpuValues.data.relativeYawScaled / YAW_SCALE;
	//			sprintf(str, "Tgt:%d Now:%ld", pivotDegreesTarget, currentYaw);

				OLED_WriteString(&myOled, str, Font_7x10, White);

				OLED_SetCursor(&myOled, 1, y_pos);

				switch(detectedIntersection) {
					case INTERSECTION_RIGHT_FRONT_OPEN:
						sprintf(str, "<- |");
						break;
					case INTERSECTION_RIGHT_SQUARE:
						sprintf(str, "<-");
						break;
					case INTERSECTION_CROSSROAD:
						sprintf(str, "CROSS");
						break;
					case INTERSECTION_LEFT_FRONT_OPEN:
						sprintf(str, "| ->");
						break;
					case INTERSECTION_LEFT_SQUARE:
						sprintf(str, "->");
						break;
					case INTERSECTION_T_ROAD:
						sprintf(str, "T");
						break;
					case INTERSECTION_UNKNOWN:
						sprintf(str, "HALL");
						break;
					case INTERSECTION_DEAD_END:
						sprintf(str, "DEAD");
				}
				OLED_WriteString(&myOled, str, Font_7x10, White);

				OLED_SetCursor(&myOled, 1, y_pos+12);

	//			sprintf(str, "%d %d %d", snapDiagLeft, snapFront, snapDiagRight);
	//			sprintf(str, "L:%3d R:%3d", myEngines.currentLeftSpeed, myEngines.currentRightSpeed);
	//	        switch(cellState) {
	//	            case CELL_INSIDE_CELL:
	//	            	sprintf(str, "C: INSIDE");
	//	            	break;
	//	            case CELL_FRONT_LINE:
	//	            	sprintf(str, "C: FRONT");
	//	            	break;
	//	            case CELL_REAR_LINE:
	//	            	sprintf(str, "C: REAR");
	//	                break;
	//	            case CELL_CROSS_FINISHED:
	//	            	sprintf(str, "C: END");
	//	            	break;
	//	        }
	//			sprintf(str, "%d %d %d", PERCEPTION_DIAG_LEFT, (PERCEPTION_FRONT_LEFT | PERCEPTION_FRONT_RIGHT), PERCEPTION_DIAG_RIGHT);
				sprintf(str, "LW:%d  RW:%d", activeLeftWall, activeRightWall);
				OLED_WriteString(&myOled, str, Font_7x10, White);
				OLED_SetCursor(&myOled, 1, y_pos+24);
				switch(cellState) {
					case CELL_INSIDE_CELL:
						sprintf(str, "C: INSIDE");
						break;
					case CELL_FRONT_LINE:
						sprintf(str, "C: FRONT");
						break;
					case CELL_REAR_LINE:
						sprintf(str, "C: REAR");
						break;
					case CELL_CROSS_FINISHED:
						sprintf(str, "C: END");
						break;
				}
				OLED_WriteString(&myOled, str, Font_7x10, White);
			} else {
				DrawRobotEyes(&myOled, detectedIntersection, currentAction, pivotDegreesTarget);
			}
			break;
		case DISPLAY_END_SCREEN:
			OLED_Fill(&myOled, Black);
			OLED_SetCursor(&myOled, 40, 20);
			OLED_WriteString(&myOled, "END", Font_16x26, White);
			break;

			/////////////////////////////////////////////// OJOS
//		    uint8_t baseW = 23;
//		    uint8_t baseH = 34;
//		    uint8_t baseX_L = 34;
//		    uint8_t baseX_R = 71;
//		    uint8_t baseY = 15;
//
//		    // Variables dinámicas
//		    uint8_t w_L = baseW, h_L = baseH;
//		    uint8_t w_R = baseW, h_R = baseH;
//		    uint8_t x_L = baseX_L, y_L = baseY;
//		    uint8_t x_R = baseX_R, y_R = baseY;
//
//		    uint8_t showEyebrow = 0;
//
//		    switch(detectedIntersection){
//		    case INTERSECTION_DEAD_END:
//		    	w_L = 13; h_L = 15; y_L = baseY + 10;
//		    	break;
//		    case INTERSECTION_RIGHT_SQUARE:
//		    case INTERSECTION_RIGHT_FRONT_OPEN:
//		        // --- MIRAR A IZQUIERDA ---
//		        // Se desplazan a la izquierda
//		        x_L = 1;
//		        x_R = 41;
//
//		        y_L = 10;
//		        // Perspectiva: Se hacen más angostos
//		        // El ojo izquierdo (el que "lidera" el giro) se hace más fino
//		        w_L = 26; // Muy fino
//		        h_L = 42; // Medio fino
//		    	break;
//		    case INTERSECTION_LEFT_SQUARE:
//		    case INTERSECTION_LEFT_FRONT_OPEN:
//				// --- MIRAR A DERECHA ---
//				// Se desplazan a la derecha
//				x_L = 64;
//				x_R = 101;
//
//				y_R = 10;
//
//				// Perspectiva
//				h_R = 42; // Medio fino
//				w_R = 26; // Muy fino
//		    	break;
//		    case INTERSECTION_CROSSROAD:
//		    case INTERSECTION_T_ROAD:
//		    	showEyebrow = 1;
//		    	y_L = baseY + 10;
//		    	y_R = baseY + 10;
//		    	break;
//		    case INTERSECTION_UNKNOWN:
//		        static uint32_t blinkTimer = 0;
//		        if (HAL_GetTick() - blinkTimer > 4000) { // Cada 4s
//		            h_L = 4; // Ojo casi cerrado
//		            h_R = 4;
//		            y_L = baseY + 15; // Centrado
//		            y_R = baseY + 15;
//
//		            if (HAL_GetTick() - blinkTimer > 4150) {
//		                blinkTimer = HAL_GetTick(); // Abrir
//		            }
//		        }
//		    	break;
//		    }
//
//		    OLED_DrawDigitalEye(&myOled, x_L, y_L, w_L, h_L);
//		    OLED_DrawDigitalEye(&myOled, x_R, y_R, w_R, h_R);
//
//		    if (showEyebrow) {
//		    	for(uint8_t i = 0; i < w_R - 5; i++) {
//		    		uint8_t pixelsToErase = 9 - (i / 2);
//
//		    		//if (pixelsToErase == 0) break;
//
//		    		OLED_DrawVerticalLine(&myOled, x_R + i, y_R, pixelsToErase, Black);
//		    	}
//		    }

//			DrawRobotEyes(&myOled, detectedIntersection, currentAction, pivotDegreesTarget);
//			break;
		case DISPLAY_IR_SENSORS:
			currentTitle = menuItems[MENU_IR_DATA];
			OLED_Fill(&myOled, Black);

			if (showIrInMillimeters) {
				// Left Column
				OLED_DrawSensorWidget(&myOled, "1", DIST_RIGHT_IR, 0, 0);
				OLED_DrawSensorWidget(&myOled, "2", DIST_DIAG_RIGHT_IR, 0, 1);
				OLED_DrawSensorWidget(&myOled, "3", DIST_FRONT_RIGHT_IR, 0, 2);

				// Center Column
				OLED_DrawSensorWidget(&myOled, "8", FILTERED_REAR_UNDER_IR, 1, 0);
				OLED_DrawSensorWidget(&myOled, "4", FILTERED_FRONT_UNDER_IR, 1, 2);

				// Right Column
				OLED_DrawSensorWidget(&myOled, "7", DIST_LEFT_IR, 2, 0);
				OLED_DrawSensorWidget(&myOled, "6", DIST_DIAG_LEFT_IR, 2, 1);
				OLED_DrawSensorWidget(&myOled, "5", DIST_FRONT_LEFT_IR, 2, 2);
			} else {
				// Left Column
				OLED_DrawSensorWidget(&myOled, "1", FILTERED_RIGHT_IR, 0, 0);
				OLED_DrawSensorWidget(&myOled, "2", FILTERED_DIAG_RIGHT_IR, 0, 1);
				OLED_DrawSensorWidget(&myOled, "3", FILTERED_FRONT_RIGHT_IR, 0, 2);

				// Center Column
				OLED_DrawSensorWidget(&myOled, "8", FILTERED_REAR_UNDER_IR, 1, 0);
				OLED_DrawSensorWidget(&myOled, "4", FILTERED_FRONT_UNDER_IR, 1, 2);

				// Right Column
				OLED_DrawSensorWidget(&myOled, "7", FILTERED_LEFT_IR, 2, 0);
				OLED_DrawSensorWidget(&myOled, "6", FILTERED_DIAG_LEFT_IR, 2, 1);
				OLED_DrawSensorWidget(&myOled, "5", FILTERED_FRONT_LEFT_IR, 2, 2);
			}
			break;
		case DISPLAY_MPU:
			currentTitle = menuItems[MENU_MPU_DATA];
			OLED_Fill(&myOled, Black);
			int32_t yawDeg = myMpuValues.data.relativeYawScaled / YAW_SCALE;

			int32_t displayYaw = yawDeg % 360;
			if (displayYaw > 180) displayYaw -= 360;
			if (displayYaw < -180) displayYaw += 360;

			snprintf(str, sizeof(str), "Yaw");
			OLED_SetCursor(&myOled, 0, y);
			OLED_WriteString(&myOled, str, Font_7x10, White);

			y += 12;
			OLED_DrawBidirectionalBar(&myOled, 0, y, 90, 8, displayYaw, 180);

			y += 12;
			snprintf(str, sizeof(str), "Gz: %d", myMpuValues.data.gyroZ);
			OLED_SetCursor(&myOled, 0, y);
			OLED_WriteString(&myOled, str, Font_7x10, White);

			y += 12;
		    snprintf(str, sizeof(str), "Ax:%d  Ay:%d", myMpuValues.data.accelX, myMpuValues.data.accelY);
		    OLED_SetCursor(&myOled, 0, y);
		    OLED_WriteString(&myOled, str, Font_7x10, White);
			break;
		case DISPLAY_WIFI:
			currentTitle = menuItems[MENU_WIFI];
			OLED_Fill(&myOled, Black);

			snprintf(str, sizeof(str), "Net: %.13s", WIFI_SSID);
			OLED_SetCursor(&myOled, 0, y);
			OLED_WriteString(&myOled, str, Font_7x10, White);

			y += 12;
			snprintf(str, sizeof(str), "PC: %.14s", WIFI_UDP_REMOTE_IP);
			OLED_SetCursor(&myOled, 0, y);
			OLED_WriteString(&myOled, str, Font_7x10, White);

			y += 12;
			sprintf(str, "L. Port: %d", WIFI_UDP_LOCAL_PORT);
			OLED_SetCursor(&myOled, 0, y);
			OLED_WriteString(&myOled, str, Font_7x10, White);

			y += 12;
			sprintf(str, "Status: ");
			OLED_SetCursor(&myOled, 0, y);
			OLED_WriteString(&myOled, str, Font_7x10, White);
			break;
		case DISPLAY_MOTORS:
			currentTitle = menuItems[MENU_DRIVE_MOTOR];
			OLED_Fill(&myOled, Black);

			y += 4;
			OLED_SetCursor(&myOled, 0, y);
			OLED_WriteString(&myOled, "L", Font_7x10, White);
			OLED_DrawBidirectionalBar(&myOled, 12, y, 78, 10, myEngines.currentLeftSpeed, 100);

			y += 16;
			OLED_SetCursor(&myOled, 0, y);
			OLED_WriteString(&myOled, "R", Font_7x10, White);
			OLED_DrawBidirectionalBar(&myOled, 12, y, 78, 10, myEngines.currentRightSpeed, 100);

			y += 16;

			snprintf(str, sizeof(str), "PWM Max: %d", myEngines.pwmMaxPeriod);
			OLED_SetCursor(&myOled, 0, y);
			OLED_WriteString(&myOled, str, Font_7x10, White);

//			y += 12;
//			if (myEngines.leftSpeed == 0 && myEngines.rightSpeed == 0) {
//				 OLED_WriteString(&myOled, "State: STOPPED", Font_7x10, White);
//			} else {
//				 OLED_WriteString(&myOled, "State: RUNNING", Font_7x10, White);
//			}

			break;
		case DISPLAY_SOFTWARE:
			currentTitle = menuItems[MENU_SOFTWARE_INFO];
			OLED_Fill(&myOled, Black);

			OLED_SetCursor(&myOled, 0, y);
			OLED_WriteString(&myOled, "Pathfinder v1.0", Font_7x10, White);

			y += 12;
			OLED_SetCursor(&myOled, 0, y);
			OLED_WriteString(&myOled, "Dev: G. Spiazzi", Font_7x10, White);

			y += 12;
		    OLED_SetCursor(&myOled, 0, y);
		    OLED_WriteString(&myOled, "Build: " __DATE__, Font_7x10, White);

		    y += 12;
		    OLED_SetCursor(&myOled, 0, y);
		    OLED_WriteString(&myOled, "Time:  " __TIME__, Font_7x10, White);
			break;
		case DISPLAY_CONFIG_START:
			currentTitle = "Set Start";
			OLED_Fill(&myOled, Black);

			char* dirStr;
			if (currentDirection == NORTH) dirStr = "NORTH";
			else if (currentDirection == EAST) dirStr = "EAST";
			else if (currentDirection == SOUTH) dirStr = "SOUTH";
			else dirStr = "WEST";

			for (int i = 0; i < 3; i++) {
				int y_pos = MENU_START_Y + (i * MENU_ITEM_HEIGHT);

				if (i == 0) sprintf(str, "Start X: %d", currentPosition.currentX);
				else if (i == 1) sprintf(str, "Start Y: %d", currentPosition.currentY);
				else if (i == 2) sprintf(str, "Dir: %s", dirStr);

				if (runConfigStep == i) {
					// Mismas dimensiones exactas que en el menú principal
					OLED_DrawFilledRect(&myOled, 15, y_pos - 1, 98, MENU_ITEM_HEIGHT - 1, White);
					OLED_SetCursor(&myOled, 15, y_pos);
					OLED_WriteString(&myOled, str, Font_7x10, Black);
				} else {
					OLED_SetCursor(&myOled, 15, y_pos);
					OLED_WriteString(&myOled, str, Font_7x10, White);
				}
			}
			break;
		case DISPLAY_CONFIG_TARGET:
			currentTitle = "Set Target";
			OLED_Fill(&myOled, Black);

			for (int i = 0; i < 2; i++) {
				int y_pos = MENU_START_Y + (i * MENU_ITEM_HEIGHT);

				if (i == 0) sprintf(str, "Target X: %d", currentPosition.targetX);
				else if (i == 1) sprintf(str, "Target Y: %d", currentPosition.targetY);

				if (runConfigStep == i) {
					OLED_DrawFilledRect(&myOled, 15, y_pos - 1, 98, MENU_ITEM_HEIGHT - 1, White);
					OLED_SetCursor(&myOled, 15, y_pos);
					OLED_WriteString(&myOled, str, Font_7x10, Black);
				} else {
					OLED_SetCursor(&myOled, 15, y_pos);
					OLED_WriteString(&myOled, str, Font_7x10, White);
				}
			}
			break;
	}

	if (page != DISPLAY_RUN)
		OLED_DrawHeader(&myOled, currentTitle, HAL_GetTick());

    if (myOled.currentPageToUpdate >= 8) {
        myOled.currentPageToUpdate = 0; // Start from page 0
        myOled.updatePageState = 0;   // Start from page state 0
    }
}

void Heartbeat() {
	if (I2C_BUS_IS_BUSY && ((HAL_GetTick() - i2c_start_timeout) > 500)) {
		mask = 0x5555; // ERROR: Parpadeo rápido y constante (100ms ON, 100ms OFF)
	} else {
		mask = 0x0AAF; // NORMAL: 4 pulsos rápidos y pausa
	}

	uint8_t write;
	write = ~(mask>>moveMask) & 1;
	moveMask++;
	moveMask ^= (moveMask & 16);
	HAL_GPIO_WritePin(LED_GPIO_Port, LED_Pin, write);
}

static void ButtonNormalPress(void) {
	if(currentMode == MODE_IDLE && currentPage == DISPLAY_MENU){
		currentSelection++;
		if (currentSelection >= totalMenuItems){
			currentSelection = 0;
			scrollOffset = 0;
		}
		detectedIntersection = Robot_IdentifyIntersection();
		//ChangeDisplayPage(DISPLAY_MENU);
	} else if (currentPage == DISPLAY_IR_SENSORS) {
		showIrInMillimeters = !showIrInMillimeters; // Alterna entre 0 y 1
	} else if (currentPage == DISPLAY_CONFIG_START) {
		if (runConfigStep == 0) {
			currentPosition.currentX = (currentPosition.currentX + 1) % 8;
		} else if (runConfigStep == 1) {
			currentPosition.currentY = (currentPosition.currentY + 1) % 8;
		} else if (runConfigStep == 2) {
			currentDirection = (currentDirection + 1) % 4;
		}
	} else if (currentPage == DISPLAY_CONFIG_TARGET) {
		if (runConfigStep == 0) {
			currentPosition.targetX = (currentPosition.targetX + 1) % 8;
		} else if (runConfigStep == 1) {
			currentPosition.targetY = (currentPosition.targetY + 1) % 8;
		}
	} else if (currentPage == DISPLAY_RUN_MODE_SELECT) {
		// Alternar entre los dos modos
		if (selectedRunMode == MODE_EXPLORING_MAZE) {
			selectedRunMode = MODE_FINDING_MARKS;
		} else {
			selectedRunMode = MODE_EXPLORING_MAZE;
		}
	} else if (currentPage == DISPLAY_RUN) {
		SHOW_EYES_SCREEN = !SHOW_EYES_SCREEN;
//		ChangeDisplayPage(DISPLAY_RUN);
	}
	return;
}

static void ButtonLongPress(void) {
	if (currentMode != MODE_IDLE) {
		Robot_Stop();
		return;
	}

	switch (currentPage) {
		case DISPLAY_MENU:
			switch(currentSelection) {
			case MENU_START:
//				Robot_ExploreMaze();
				selectedRunMode = MODE_EXPLORING_MAZE; // Modo por defecto al entrar
				currentPage = DISPLAY_RUN_MODE_SELECT;
//				currentPage = DISPLAY_CONFIG_START;
//				runConfigStep = 0;
				break;
			case MENU_IR_DATA:
				currentPage = DISPLAY_IR_SENSORS;
				ChangeDisplayPage(DISPLAY_IR_SENSORS);
				break;
			case MENU_MPU_DATA:
				currentPage = DISPLAY_MPU;
				ChangeDisplayPage(DISPLAY_MPU);
				break;
			case MENU_WIFI:
				currentPage = DISPLAY_WIFI;
				ChangeDisplayPage(DISPLAY_WIFI);
				break;
			case MENU_DRIVE_MOTOR:
				currentPage = DISPLAY_MOTORS;
				ChangeDisplayPage(DISPLAY_MOTORS);
				break;
			case MENU_SOFTWARE_INFO:
				currentPage = DISPLAY_SOFTWARE;
				ChangeDisplayPage(DISPLAY_SOFTWARE);
				break;
			}
			break;
		case DISPLAY_CONFIG_START:
			runConfigStep++;
			if (runConfigStep > 2) {
				runConfigStep = 0;

				if (selectedRunMode == MODE_FINDING_MARKS) {
					Robot_StartFindingMarks(); // Saltea el Target y arranca
				} else {
					currentPage = DISPLAY_CONFIG_TARGET; // Va a configurar el Target
				}
			}
			break;
		case DISPLAY_CONFIG_TARGET:
			runConfigStep++;
			if (runConfigStep > 1) {
				Robot_ExploreMaze();
			}
			break;
		case DISPLAY_RUN_MODE_SELECT:
			// Confirmamos el modo y pasamos a configurar el inicio
			currentPage = DISPLAY_CONFIG_START;
			runConfigStep = 0;
			break;

		default:
			currentPage = DISPLAY_MENU;
			ChangeDisplayPage(DISPLAY_MENU);
			break;
	}

//	OLED_SetCursor(&myOled, 82, 33);
//	sprintf(strAux, "R:%3hd%c", myEngines.rightSpeed, '%');
//	OLED_WriteString(&myOled, strAux, Font_7x10, White);
}

/* USER CODE END 0 */

int main(void)
{

  /* USER CODE BEGIN 1 */
	mask = 0xAAF;
	moveMask = 0;
	//heartbeat = HEARTBEAT_IDLE;
	//heartbeatmask = 0x80000000;
	t1MS = 4;
	t10MS = 10;
	t100MS = 10;
	t1S = 10;
	tOutAliveUDP = 50;

	esp01.DoCHPD = ESP01DoCHPD;
	esp01.WriteByteToBufRX = ESP01WriteByteToBufRX;
	esp01.WriteUSARTByte = ESP01WriteUSARTByte;

	unerbusESP01.MyDataReady = DecodeCMD;
	unerbusESP01.WriteUSARTByte = NULL;
	unerbusESP01.rx.buf = bufRXESP01;
	unerbusESP01.rx.maxIndexRingBuf = (SIZEBUFRXESP01 - 1);
	unerbusESP01.tx.buf = bufTXESP01;
	unerbusESP01.tx.maxIndexRingBuf = (SIZEBUFTXESP01 - 1);

	unerbusPC.MyDataReady = DecodeCMD;
	unerbusPC.WriteUSARTByte = NULL;
	unerbusPC.rx.buf = bufRXPC;
	unerbusPC.rx.maxIndexRingBuf = (SIZEBUFRXPC - 1);
	unerbusPC.tx.buf = bufTXPC;
	unerbusPC.tx.maxIndexRingBuf = (SIZEBUFTXPC - 1);
  /* USER CODE END 1 */

  /* MCU Configuration--------------------------------------------------------*/

  /* Reset of all peripherals, Initializes the Flash interface and the Systick. */
  HAL_Init();

  /* Configure the system clock */
  SystemClock_Config();

  /* Initialize all configured peripherals */
  MX_GPIO_Init();
  MX_DMA_Init();
  MX_USB_DEVICE_Init();
  MX_ADC1_Init();
  MX_I2C2_Init();
  MX_TIM1_Init();
  MX_TIM4_Init();
  MX_USART1_UART_Init();
  /* USER CODE BEGIN 2 */
  HAL_Delay(100);

  // Register callbacks for I2C Operations
  Port_I2C_Register_DMA_Rx_Callback(MPU_Read_Completed_Callback, &myMpuValues);
  Port_I2C_Register_DMA_Tx_Callback(OLED_Write_Completed_Callback, &myOled);

  // OLED Initialization
  if (OLED_Init(&myOled, OLED_I2C_ADDR, &hi2c2) != OLED_OK){
      while (1) {
          HAL_GPIO_TogglePin(LED_GPIO_Port, LED_Pin);
          HAL_Delay(500);
      }
  }

  // OLED Start Image
  OLED_DrawBitmap(&myOled, OLED_WIDTH, OLED_HEIGHT, varEeprom);
  myOled.currentPageToUpdate = 0;
  myOled.updatePageState = 0;

  while (myOled.currentPageToUpdate < 8) {
      I2C_State_Control();
  }

  currentPage = DISPLAY_MENU;
  ChangeDisplayPage(DISPLAY_MENU);

  currentSelection = 0;
  scrollOffset = 0;

  HAL_Delay(1200);

  // MPU6050 Initialization
  if (MPU6050_Init(&myMpuValues, MPU6050_ADDR, &hi2c2) != MPU6050_OK) {
      while (1) {
          HAL_GPIO_TogglePin(LED_GPIO_Port, LED_Pin);
          HAL_Delay(100);
      }
  }

  // MPU6050 Calibration
  if (MPU6050_Calibrate(&myMpuValues) != MPU6050_OK) {
      while (1) {
          HAL_GPIO_TogglePin(LED_GPIO_Port, LED_Pin);
          HAL_Delay(3000);
      }
  }

  I2C_BUS_IS_BUSY = 0;

  HAL_Delay(1500);

  // Engines Initialization
  ENGINE_Init(&myEngines);

  // Voltage used to calibrate the PIDs
  myEngines.nominalVoltage = PID_VOLTAGE;

  // Voltage measured with the multi-meter before use
  ENGINE_SetBatteryVoltage(&myEngines, CURRENT_VOLTAGE);

  HAL_Delay(500);

  // Buttons Initialization
  BUTTON_Init(&myButton1, SW1_GPIO_Port, SW1_Pin);

  BUTTON_Register_PressReleasedCallback(&myButton1, ButtonNormalPress);
  BUTTON_Register_LongPressCallback(&myButton1, ButtonLongPress);

  // PID Initialization
  PID_Init(&mySmoothTurnValues, 10, 0, 10, -90, 90);
  mySmoothTurnValues.base = SMOOTH_TURN_BASE_SPEED;
  PID_Init(&myTurnValues, 45, 0, 10, -65, 65);
//  PID_Init(&myTurnValues, 45, 0, 2500, -65, 65);
//  PID_Init(&myWallValues, 10, 0, 1500, -55, 55); // P = 1 // 45
  PID_Init(&myWallValues, 70, 0, 5500, -45, 45);
  myTurnValues.base = TURN_MIN_PWM;
  myWallValues.base = 43;

  PID_Init(&myReverseValues, 70, 0, 6000, -45, 45);
  myReverseValues.base = 45;
//  PID_Init(&myStopValues, 4000, 0, 300, -80, 35);
  PID_Init(&myStopValues, 200, 0, 800, -50, 40);
  myStopValues.base = 35;
  // IR Sensors Initialization
  Infrared_Init(&myInfraredValues);

  // Communication Initialization
  CDC_AttachRxData(USBReceive);

  ESP01_Init(&esp01);
  UNERBUS_Init(&unerbusESP01);
  UNERBUS_Init(&unerbusPC);

  ESP01_AttachChangeState(ESP01ChangeState);
  ESP01_SetWIFI(WIFI_SSID, WIFI_PASSWORD);
  ESP01_StartUDP(WIFI_UDP_REMOTE_IP, WIFI_UDP_REMOTE_PORT, WIFI_UDP_LOCAL_PORT);

  HAL_UART_Receive_IT(&huart1, &dataRXESP01, 1);

  // Timers Initialization
  HAL_TIM_Base_Start_IT(&htim1);

  HAL_TIM_Base_Start(&htim4);
  HAL_TIM_PWM_Start(&htim4, TIM_CHANNEL_1);
  HAL_TIM_PWM_Start(&htim4, TIM_CHANNEL_2);
  HAL_TIM_PWM_Start(&htim4, TIM_CHANNEL_3);
  HAL_TIM_PWM_Start(&htim4, TIM_CHANNEL_4);
  __HAL_TIM_SET_COMPARE(&htim4, TIM_CHANNEL_1, 0);
  __HAL_TIM_SET_COMPARE(&htim4, TIM_CHANNEL_2, 0);
  __HAL_TIM_SET_COMPARE(&htim4, TIM_CHANNEL_3, 0);
  __HAL_TIM_SET_COMPARE(&htim4, TIM_CHANNEL_4, 0);

  // ROBOT NAVIGATION INICIALIZATION
  currentAction = ACTION_IDLE;

  detectedIntersection = INTERSECTION_UNKNOWN;
  pivotDegreesTarget = 0;

  cellState = CELL_INSIDE_CELL;

  marksFound = 0;
  /* USER CODE END 2 */

  /* Infinite loop */
  while (1)
  {

    /* USER CODE BEGIN 3 */
	  if(on1MS)
		  Do1ms();

	  if(!t10MS)
		  Do10ms();

	  if(!t20MS)
		  Do20ms();

	  if(!t100MS)
		  Do100ms();

	  if(!t1S)
		  Do1s();

	  I2C_State_Control();

	  ESP01_Task();

	  UNERBUS_Task(&unerbusESP01);

	  UNERBUS_Task(&unerbusPC);

	  BUTTON_Update(&myButton1);

	  if(!tOutAliveUDP){
		  tOutAliveUDP = 50;
		  UNERBUS_WriteByte(&unerbusESP01, ACKNOWLEDGE);
		  UNERBUS_Send(&unerbusESP01, ALIVE, 2);

		  //UNERBUS_WriteConstString(&unerbusPC, "UNER\x03:\xF0\x0D\xC8", 0);
		  //UNERBUS_WriteConstString(&unerbusPC, " El ALIVE", 1);
	  }

	  if(unerbusESP01.tx.iRead != unerbusESP01.tx.iWrite){
		  w.u8[0] = unerbusESP01.tx.iWrite - unerbusESP01.tx.iRead;
		  w.u8[0] &= unerbusESP01.tx.maxIndexRingBuf;
		  if(ESP01_Send(unerbusESP01.tx.buf, unerbusESP01.tx.iRead, w.u8[0], unerbusESP01.tx.maxIndexRingBuf+1) == ESP01_SEND_READY)
			  unerbusESP01.tx.iRead = unerbusESP01.tx.iWrite;
	  }

	  if(unerbusPC.tx.iRead != unerbusPC.tx.iWrite){
		  if(unerbusPC.tx.iRead < unerbusPC.tx.iWrite)
			  w.u8[0] = unerbusPC.tx.iWrite - unerbusPC.tx.iRead;
		  else
			  w.u8[0] = unerbusPC.tx.maxIndexRingBuf+1 - unerbusPC.tx.iRead;

		  if(CDC_Transmit_FS(&unerbusPC.tx.buf[unerbusPC.tx.iRead], w.u8[0]) == USBD_OK){
			  unerbusPC.tx.iRead += w.u8[0];
			  unerbusPC.tx.iRead &= unerbusPC.tx.maxIndexRingBuf;
		  }
	  }
  }
  /* USER CODE END 3 */
}

void SystemClock_Config(void)
{
  RCC_OscInitTypeDef RCC_OscInitStruct = {0};
  RCC_ClkInitTypeDef RCC_ClkInitStruct = {0};
  RCC_PeriphCLKInitTypeDef PeriphClkInit = {0};

  /** Initializes the RCC Oscillators according to the specified parameters
  * in the RCC_OscInitTypeDef structure.
  */
  RCC_OscInitStruct.OscillatorType = RCC_OSCILLATORTYPE_HSE;
  RCC_OscInitStruct.HSEState = RCC_HSE_ON;
  RCC_OscInitStruct.HSEPredivValue = RCC_HSE_PREDIV_DIV1;
  RCC_OscInitStruct.HSIState = RCC_HSI_ON;
  RCC_OscInitStruct.PLL.PLLState = RCC_PLL_ON;
  RCC_OscInitStruct.PLL.PLLSource = RCC_PLLSOURCE_HSE;
  RCC_OscInitStruct.PLL.PLLMUL = RCC_PLL_MUL9;
  if (HAL_RCC_OscConfig(&RCC_OscInitStruct) != HAL_OK)
  {
    Error_Handler();
  }

  /** Initializes the CPU, AHB and APB buses clocks
  */
  RCC_ClkInitStruct.ClockType = RCC_CLOCKTYPE_HCLK|RCC_CLOCKTYPE_SYSCLK
                              |RCC_CLOCKTYPE_PCLK1|RCC_CLOCKTYPE_PCLK2;
  RCC_ClkInitStruct.SYSCLKSource = RCC_SYSCLKSOURCE_PLLCLK;
  RCC_ClkInitStruct.AHBCLKDivider = RCC_SYSCLK_DIV1;
  RCC_ClkInitStruct.APB1CLKDivider = RCC_HCLK_DIV2;
  RCC_ClkInitStruct.APB2CLKDivider = RCC_HCLK_DIV1;

  if (HAL_RCC_ClockConfig(&RCC_ClkInitStruct, FLASH_LATENCY_2) != HAL_OK)
  {
    Error_Handler();
  }
  PeriphClkInit.PeriphClockSelection = RCC_PERIPHCLK_ADC|RCC_PERIPHCLK_USB;
  PeriphClkInit.AdcClockSelection = RCC_ADCPCLK2_DIV6;
  PeriphClkInit.UsbClockSelection = RCC_USBCLKSOURCE_PLL_DIV1_5;
  if (HAL_RCCEx_PeriphCLKConfig(&PeriphClkInit) != HAL_OK)
  {
    Error_Handler();
  }
}

static void MX_ADC1_Init(void)
{

  ADC_ChannelConfTypeDef sConfig = {0};

  /** Common config
  */
  hadc1.Instance = ADC1;
  hadc1.Init.ScanConvMode = ADC_SCAN_ENABLE;
  hadc1.Init.ContinuousConvMode = DISABLE;
  hadc1.Init.DiscontinuousConvMode = DISABLE;
  hadc1.Init.ExternalTrigConv = ADC_SOFTWARE_START;
  hadc1.Init.DataAlign = ADC_DATAALIGN_RIGHT;
  hadc1.Init.NbrOfConversion = 8;
  if (HAL_ADC_Init(&hadc1) != HAL_OK)
  {
    Error_Handler();
  }

  /** Configure Regular Channel
  */
  sConfig.Channel = ADC_CHANNEL_0;
  sConfig.Rank = ADC_REGULAR_RANK_1;
  sConfig.SamplingTime = ADC_SAMPLETIME_55CYCLES_5;
  if (HAL_ADC_ConfigChannel(&hadc1, &sConfig) != HAL_OK)
  {
    Error_Handler();
  }

  /** Configure Regular Channel
  */
  sConfig.Channel = ADC_CHANNEL_1;
  sConfig.Rank = ADC_REGULAR_RANK_2;
  if (HAL_ADC_ConfigChannel(&hadc1, &sConfig) != HAL_OK)
  {
    Error_Handler();
  }

  /** Configure Regular Channel
  */
  sConfig.Channel = ADC_CHANNEL_2;
  sConfig.Rank = ADC_REGULAR_RANK_3;
  if (HAL_ADC_ConfigChannel(&hadc1, &sConfig) != HAL_OK)
  {
    Error_Handler();
  }

  /** Configure Regular Channel
  */
  sConfig.Channel = ADC_CHANNEL_3;
  sConfig.Rank = ADC_REGULAR_RANK_4;
  if (HAL_ADC_ConfigChannel(&hadc1, &sConfig) != HAL_OK)
  {
    Error_Handler();
  }

  /** Configure Regular Channel
  */
  sConfig.Channel = ADC_CHANNEL_4;
  sConfig.Rank = ADC_REGULAR_RANK_5;
  if (HAL_ADC_ConfigChannel(&hadc1, &sConfig) != HAL_OK)
  {
    Error_Handler();
  }

  /** Configure Regular Channel
  */
  sConfig.Channel = ADC_CHANNEL_5;
  sConfig.Rank = ADC_REGULAR_RANK_6;
  if (HAL_ADC_ConfigChannel(&hadc1, &sConfig) != HAL_OK)
  {
    Error_Handler();
  }

  /** Configure Regular Channel
  */
  sConfig.Channel = ADC_CHANNEL_6;
  sConfig.Rank = ADC_REGULAR_RANK_7;
  if (HAL_ADC_ConfigChannel(&hadc1, &sConfig) != HAL_OK)
  {
    Error_Handler();
  }

  /** Configure Regular Channel
  */
  sConfig.Channel = ADC_CHANNEL_7;
  sConfig.Rank = ADC_REGULAR_RANK_8;
  if (HAL_ADC_ConfigChannel(&hadc1, &sConfig) != HAL_OK)
  {
    Error_Handler();
  }

}

static void MX_I2C2_Init(void)
{

  hi2c2.Instance = I2C2;
  hi2c2.Init.ClockSpeed = 400000;
  hi2c2.Init.DutyCycle = I2C_DUTYCYCLE_2;
  hi2c2.Init.OwnAddress1 = 0;
  hi2c2.Init.AddressingMode = I2C_ADDRESSINGMODE_7BIT;
  hi2c2.Init.DualAddressMode = I2C_DUALADDRESS_DISABLE;
  hi2c2.Init.OwnAddress2 = 0;
  hi2c2.Init.GeneralCallMode = I2C_GENERALCALL_DISABLE;
  hi2c2.Init.NoStretchMode = I2C_NOSTRETCH_DISABLE;
  if (HAL_I2C_Init(&hi2c2) != HAL_OK)
  {
    Error_Handler();
  }

}

static void MX_TIM1_Init(void)
{

  TIM_ClockConfigTypeDef sClockSourceConfig = {0};
  TIM_MasterConfigTypeDef sMasterConfig = {0};

  htim1.Instance = TIM1;
  htim1.Init.Prescaler = 71;
  htim1.Init.CounterMode = TIM_COUNTERMODE_UP;
  htim1.Init.Period = 249;
  htim1.Init.ClockDivision = TIM_CLOCKDIVISION_DIV1;
  htim1.Init.RepetitionCounter = 0;
  htim1.Init.AutoReloadPreload = TIM_AUTORELOAD_PRELOAD_DISABLE;
  if (HAL_TIM_Base_Init(&htim1) != HAL_OK)
  {
    Error_Handler();
  }
  sClockSourceConfig.ClockSource = TIM_CLOCKSOURCE_INTERNAL;
  if (HAL_TIM_ConfigClockSource(&htim1, &sClockSourceConfig) != HAL_OK)
  {
    Error_Handler();
  }
  sMasterConfig.MasterOutputTrigger = TIM_TRGO_RESET;
  sMasterConfig.MasterSlaveMode = TIM_MASTERSLAVEMODE_DISABLE;
  if (HAL_TIMEx_MasterConfigSynchronization(&htim1, &sMasterConfig) != HAL_OK)
  {
    Error_Handler();
  }

}

static void MX_TIM4_Init(void)
{

  TIM_ClockConfigTypeDef sClockSourceConfig = {0};
  TIM_MasterConfigTypeDef sMasterConfig = {0};
  TIM_OC_InitTypeDef sConfigOC = {0};

  htim4.Instance = TIM4;
  htim4.Init.Prescaler = 71;
  htim4.Init.CounterMode = TIM_COUNTERMODE_UP;
  htim4.Init.Period = 9999;
  htim4.Init.ClockDivision = TIM_CLOCKDIVISION_DIV1;
  htim4.Init.AutoReloadPreload = TIM_AUTORELOAD_PRELOAD_DISABLE;
  if (HAL_TIM_Base_Init(&htim4) != HAL_OK)
  {
    Error_Handler();
  }
  sClockSourceConfig.ClockSource = TIM_CLOCKSOURCE_INTERNAL;
  if (HAL_TIM_ConfigClockSource(&htim4, &sClockSourceConfig) != HAL_OK)
  {
    Error_Handler();
  }
  if (HAL_TIM_PWM_Init(&htim4) != HAL_OK)
  {
    Error_Handler();
  }
  sMasterConfig.MasterOutputTrigger = TIM_TRGO_RESET;
  sMasterConfig.MasterSlaveMode = TIM_MASTERSLAVEMODE_DISABLE;
  if (HAL_TIMEx_MasterConfigSynchronization(&htim4, &sMasterConfig) != HAL_OK)
  {
    Error_Handler();
  }
  sConfigOC.OCMode = TIM_OCMODE_PWM1;
  sConfigOC.Pulse = 0;
  sConfigOC.OCPolarity = TIM_OCPOLARITY_HIGH;
  sConfigOC.OCFastMode = TIM_OCFAST_DISABLE;
  if (HAL_TIM_PWM_ConfigChannel(&htim4, &sConfigOC, TIM_CHANNEL_1) != HAL_OK)
  {
    Error_Handler();
  }
  if (HAL_TIM_PWM_ConfigChannel(&htim4, &sConfigOC, TIM_CHANNEL_2) != HAL_OK)
  {
    Error_Handler();
  }
  if (HAL_TIM_PWM_ConfigChannel(&htim4, &sConfigOC, TIM_CHANNEL_3) != HAL_OK)
  {
    Error_Handler();
  }
  if (HAL_TIM_PWM_ConfigChannel(&htim4, &sConfigOC, TIM_CHANNEL_4) != HAL_OK)
  {
    Error_Handler();
  }
  HAL_TIM_MspPostInit(&htim4);

}

static void MX_USART1_UART_Init(void)
{

  huart1.Instance = USART1;
  huart1.Init.BaudRate = 115200;
  huart1.Init.WordLength = UART_WORDLENGTH_8B;
  huart1.Init.StopBits = UART_STOPBITS_1;
  huart1.Init.Parity = UART_PARITY_NONE;
  huart1.Init.Mode = UART_MODE_TX_RX;
  huart1.Init.HwFlowCtl = UART_HWCONTROL_NONE;
  huart1.Init.OverSampling = UART_OVERSAMPLING_16;
  if (HAL_UART_Init(&huart1) != HAL_OK)
  {
    Error_Handler();
  }

}

static void MX_DMA_Init(void)
{

  /* DMA controller clock enable */
  __HAL_RCC_DMA1_CLK_ENABLE();

  /* DMA interrupt init */
  /* DMA1_Channel1_IRQn interrupt configuration */
  HAL_NVIC_SetPriority(DMA1_Channel1_IRQn, 0, 0);
  HAL_NVIC_EnableIRQ(DMA1_Channel1_IRQn);
  /* DMA1_Channel4_IRQn interrupt configuration */
  HAL_NVIC_SetPriority(DMA1_Channel4_IRQn, 0, 0);
  HAL_NVIC_EnableIRQ(DMA1_Channel4_IRQn);
  /* DMA1_Channel5_IRQn interrupt configuration */
  HAL_NVIC_SetPriority(DMA1_Channel5_IRQn, 0, 0);
  HAL_NVIC_EnableIRQ(DMA1_Channel5_IRQn);

}

static void MX_GPIO_Init(void)
{
  GPIO_InitTypeDef GPIO_InitStruct = {0};

  /* GPIO Ports Clock Enable */
  __HAL_RCC_GPIOC_CLK_ENABLE();
  __HAL_RCC_GPIOD_CLK_ENABLE();
  __HAL_RCC_GPIOA_CLK_ENABLE();
  __HAL_RCC_GPIOB_CLK_ENABLE();

  /*Configure GPIO pin Output Level */
  HAL_GPIO_WritePin(LED_GPIO_Port, LED_Pin, GPIO_PIN_RESET);

  /*Configure GPIO pin Output Level */
  HAL_GPIO_WritePin(CH_EN_GPIO_Port, CH_EN_Pin, GPIO_PIN_RESET);

  /*Configure GPIO pin : LED_Pin */
  GPIO_InitStruct.Pin = LED_Pin;
  GPIO_InitStruct.Mode = GPIO_MODE_OUTPUT_PP;
  GPIO_InitStruct.Pull = GPIO_NOPULL;
  GPIO_InitStruct.Speed = GPIO_SPEED_FREQ_LOW;
  HAL_GPIO_Init(LED_GPIO_Port, &GPIO_InitStruct);

  /*Configure GPIO pin : SW1_Pin */
  GPIO_InitStruct.Pin = SW1_Pin;
  GPIO_InitStruct.Mode = GPIO_MODE_INPUT;
  GPIO_InitStruct.Pull = GPIO_PULLUP;
  HAL_GPIO_Init(SW1_GPIO_Port, &GPIO_InitStruct);

  /*Configure GPIO pin : SW0_Pin */
  GPIO_InitStruct.Pin = SW0_Pin;
  GPIO_InitStruct.Mode = GPIO_MODE_INPUT;
  GPIO_InitStruct.Pull = GPIO_NOPULL;
  HAL_GPIO_Init(SW0_GPIO_Port, &GPIO_InitStruct);

  /*Configure GPIO pin : CH_EN_Pin */
  GPIO_InitStruct.Pin = CH_EN_Pin;
  GPIO_InitStruct.Mode = GPIO_MODE_OUTPUT_PP;
  GPIO_InitStruct.Pull = GPIO_NOPULL;
  GPIO_InitStruct.Speed = GPIO_SPEED_FREQ_LOW;
  HAL_GPIO_Init(CH_EN_GPIO_Port, &GPIO_InitStruct);

}

void Error_Handler(void)
{
  /* USER CODE BEGIN Error_Handler_Debug */
  /* User can add his own implementation to report the HAL error return state */
  __disable_irq();
  while (1)
  {
	  mask = 0x5555;
  }
  /* USER CODE END Error_Handler_Debug */
}
